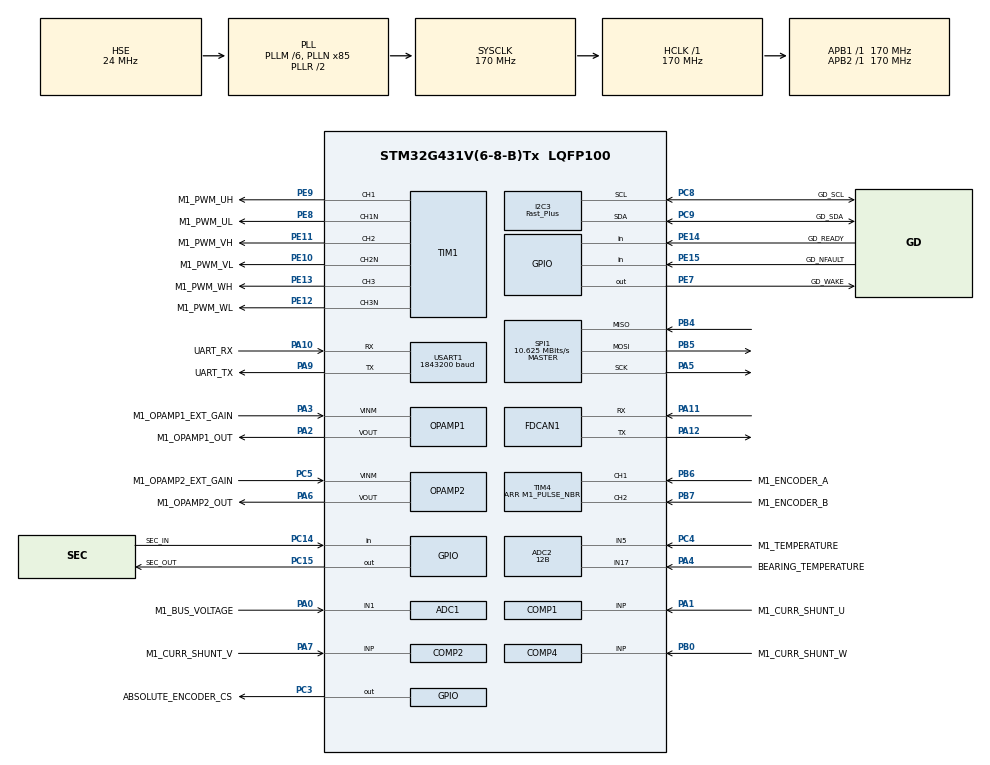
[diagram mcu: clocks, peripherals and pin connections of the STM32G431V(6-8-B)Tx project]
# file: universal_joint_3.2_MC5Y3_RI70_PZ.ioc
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ADC1.Channel-1\#ChannelRegularConversion=ADC_CHANNEL_1
ADC1.ClockPrescaler=ADC_CLOCK_ASYNC_DIV1
ADC1.ContinuousConvMode=DISABLE
ADC1.DMAContinuousRequests=DISABLE
ADC1.DataAlign=ADC_DATAALIGN_LEFT
ADC1.DiscontinuousConvMode=DISABLE
ADC1.EOCSelection=ADC_EOC_SINGLE_CONV
ADC1.EnableAnalogWatchDog1=false
ADC1.EnableAnalogWatchDog2=false
ADC1.EnableAnalogWatchDog3=false
ADC1.EnableInjectedConversion=ENABLE
ADC1.EnableRegularConversion=ENABLE
ADC1.ExternalTrigConv=ADC_SOFTWARE_START
ADC1.ExternalTrigConvEdge=ADC_EXTERNALTRIGCONVEDGE_NONE
ADC1.ExternalTrigInjecConv=ADC_EXTERNALTRIGINJEC_T1_TRGO
ADC1.ExternalTrigInjecConvEdge=ADC_EXTERNALTRIGINJECCONV_EDGE_RISING
ADC1.InjNumberOfConversion=1
ADC1.InjectedChannel-1\#ChannelInjectedConversion=ADC_CHANNEL_3
ADC1.InjectedConvMode=None
ADC1.InjectedOffset-1\#ChannelInjectedConversion=0
ADC1.InjectedOffsetNumber-1\#ChannelInjectedConversion=ADC_OFFSET_NONE
ADC1.InjectedRank-1\#ChannelInjectedConversion=1
ADC1.InjectedSamplingTime-1\#ChannelInjectedConversion=ADC_SAMPLETIME_6CYCLES_5
ADC1.LowPowerAutoWait=DISABLE
ADC1.NbrOfConversion=1
ADC1.NbrOfConversionFlag=1
ADC1.Offset-1\#ChannelRegularConversion=0
ADC1.OffsetNumber-1\#ChannelRegularConversion=ADC_OFFSET_NONE
ADC1.Overrun=ADC_OVR_DATA_PRESERVED
ADC1.Rank-1\#ChannelRegularConversion=1
ADC1.Resolution=ADC_RESOLUTION_12B
ADC1.SamplingTime-1\#ChannelRegularConversion=ADC_SAMPLETIME_47CYCLES_5
ADC1.ScanConvMode=ADC_SCAN_DISABLE
ADC1.master=1
ADC2.Channel-1\#ChannelRegularConversion=ADC_CHANNEL_5
ADC2.Channel-2\#ChannelRegularConversion=ADC_CHANNEL_17
ADC2.ClockPrescaler=ADC_CLOCK_ASYNC_DIV1
ADC2.ContinuousConvMode=DISABLE
ADC2.DMAContinuousRequests=DISABLE
ADC2.DataAlign=ADC_DATAALIGN_LEFT
ADC2.DiscontinuousConvMode=DISABLE
ADC2.EOCSelection=ADC_EOC_SINGLE_CONV
ADC2.EnableAnalogWatchDog1=false
ADC2.EnableAnalogWatchDog2=false
ADC2.EnableAnalogWatchDog3=false
ADC2.EnableInjectedConversion=ENABLE
ADC2.EnableRegularConversion=ENABLE
ADC2.ExternalTrigConv=ADC_SOFTWARE_START
ADC2.ExternalTrigConvEdge=ADC_EXTERNALTRIGCONVEDGE_NONE
ADC2.ExternalTrigInjecConv=ADC_EXTERNALTRIGINJEC_T1_TRGO
ADC2.ExternalTrigInjecConvEdge=ADC_EXTERNALTRIGINJECCONV_EDGE_RISING
ADC2.InjNumberOfConversion=1
ADC2.InjectedChannel-1\#ChannelInjectedConversion=ADC_CHANNEL_3
ADC2.InjectedConvMode=None
ADC2.InjectedOffset-1\#ChannelInjectedConversion=0
ADC2.InjectedOffsetNumber-1\#ChannelInjectedConversion=ADC_OFFSET_NONE
ADC2.InjectedRank-1\#ChannelInjectedConversion=1
ADC2.InjectedSamplingTime-1\#ChannelInjectedConversion=ADC_SAMPLETIME_6CYCLES_5
ADC2.LowPowerAutoWait=DISABLE
ADC2.NbrOfConversion=2
ADC2.NbrOfConversionFlag=1
ADC2.Offset-1\#ChannelRegularConversion=0
ADC2.OffsetNumber-1\#ChannelRegularConversion=ADC_OFFSET_NONE
ADC2.OffsetNumber-2\#ChannelRegularConversion=ADC_OFFSET_NONE
ADC2.Overrun=ADC_OVR_DATA_PRESERVED
ADC2.Rank-1\#ChannelRegularConversion=1
ADC2.Rank-2\#ChannelRegularConversion=2
ADC2.Resolution=ADC_RESOLUTION_12B
ADC2.SamplingTime-1\#ChannelRegularConversion=ADC_SAMPLETIME_47CYCLES_5
ADC2.SamplingTime-2\#ChannelRegularConversion=ADC_SAMPLETIME_47CYCLES_5
ADC2.ScanConvMode=ADC_SCAN_ENABLE
COMP1.Output=COMP_OUTPUT_TIM1BKIN2
COMP2.Output=COMP_OUTPUT_TIM1BKIN2
COMP4.Output=COMP_OUTPUT_TIM1BKIN2
Dma.Request0=USART1_RX
Dma.Request1=USART1_TX
Dma.Request2=SPI1_RX
Dma.Request3=SPI1_TX
Dma.SPI1_RX.2.Direction=DMA_PERIPH_TO_MEMORY
Dma.SPI1_RX.2.EventEnable=DISABLE
Dma.SPI1_RX.2.Instance=DMA1_Channel1
Dma.SPI1_RX.2.MemDataAlignment=DMA_MDATAALIGN_BYTE
Dma.SPI1_RX.2.MemInc=DMA_MINC_ENABLE
Dma.SPI1_RX.2.Mode=DMA_NORMAL
Dma.SPI1_RX.2.PeriphDataAlignment=DMA_PDATAALIGN_BYTE
Dma.SPI1_RX.2.PeriphInc=DMA_PINC_DISABLE
Dma.SPI1_RX.2.Polarity=HAL_DMAMUX_REQ_GEN_RISING
Dma.SPI1_RX.2.Priority=DMA_PRIORITY_LOW
Dma.SPI1_RX.2.RequestNumber=1
Dma.SPI1_RX.2.SignalID=NONE
Dma.SPI1_RX.2.SyncEnable=DISABLE
Dma.SPI1_RX.2.SyncPolarity=HAL_DMAMUX_SYNC_NO_EVENT
Dma.SPI1_RX.2.SyncRequestNumber=1
Dma.SPI1_RX.2.SyncSignalID=NONE
Dma.SPI1_TX.3.Direction=DMA_MEMORY_TO_PERIPH
Dma.SPI1_TX.3.EventEnable=DISABLE
Dma.SPI1_TX.3.Instance=DMA1_Channel4
Dma.SPI1_TX.3.MemDataAlignment=DMA_MDATAALIGN_BYTE
Dma.SPI1_TX.3.MemInc=DMA_MINC_ENABLE
Dma.SPI1_TX.3.Mode=DMA_NORMAL
Dma.SPI1_TX.3.PeriphDataAlignment=DMA_PDATAALIGN_BYTE
Dma.SPI1_TX.3.PeriphInc=DMA_PINC_DISABLE
Dma.SPI1_TX.3.Polarity=HAL_DMAMUX_REQ_GEN_RISING
Dma.SPI1_TX.3.Priority=DMA_PRIORITY_LOW
Dma.SPI1_TX.3.RequestNumber=1
Dma.SPI1_TX.3.SignalID=NONE
Dma.SPI1_TX.3.SyncEnable=DISABLE
Dma.SPI1_TX.3.SyncPolarity=HAL_DMAMUX_SYNC_NO_EVENT
Dma.SPI1_TX.3.SyncRequestNumber=1
Dma.SPI1_TX.3.SyncSignalID=NONE
Dma.USART1_RX.0.Direction=DMA_PERIPH_TO_MEMORY
Dma.USART1_RX.0.EventEnable=DISABLE
Dma.USART1_RX.0.Instance=DMA1_Channel2
Dma.USART1_RX.0.MemDataAlignment=DMA_MDATAALIGN_BYTE
Dma.USART1_RX.0.MemInc=DMA_MINC_ENABLE
Dma.USART1_RX.0.Mode=DMA_NORMAL
Dma.USART1_RX.0.PeriphDataAlignment=DMA_PDATAALIGN_BYTE
Dma.USART1_RX.0.PeriphInc=DMA_PINC_DISABLE
Dma.USART1_RX.0.Polarity=HAL_DMAMUX_REQ_GEN_RISING
Dma.USART1_RX.0.Priority=DMA_PRIORITY_LOW
Dma.USART1_RX.0.RequestNumber=1
Dma.USART1_RX.0.SignalID=NONE
Dma.USART1_RX.0.SyncEnable=DISABLE
Dma.USART1_RX.0.SyncPolarity=HAL_DMAMUX_SYNC_NO_EVENT
Dma.USART1_RX.0.SyncRequestNumber=1
Dma.USART1_RX.0.SyncSignalID=NONE
Dma.USART1_TX.1.Direction=DMA_MEMORY_TO_PERIPH
Dma.USART1_TX.1.EventEnable=DISABLE
Dma.USART1_TX.1.Instance=DMA1_Channel3
Dma.USART1_TX.1.MemDataAlignment=DMA_MDATAALIGN_BYTE
Dma.USART1_TX.1.MemInc=DMA_MINC_ENABLE
Dma.USART1_TX.1.Mode=DMA_NORMAL
Dma.USART1_TX.1.PeriphDataAlignment=DMA_PDATAALIGN_BYTE
Dma.USART1_TX.1.PeriphInc=DMA_PINC_DISABLE
Dma.USART1_TX.1.Polarity=HAL_DMAMUX_REQ_GEN_RISING
Dma.USART1_TX.1.Priority=DMA_PRIORITY_LOW
Dma.USART1_TX.1.RequestNumber=1
Dma.USART1_TX.1.SignalID=NONE
Dma.USART1_TX.1.SyncEnable=DISABLE
Dma.USART1_TX.1.SyncPolarity=HAL_DMAMUX_SYNC_NO_EVENT
Dma.USART1_TX.1.SyncRequestNumber=1
Dma.USART1_TX.1.SyncSignalID=NONE
ExtraMW=MotorControl
ExtraMW.MotorControl.Config=MotorControl
ExtraMW.MotorControl.Mode=MotorControl
ExtraMW.MotorControl.Root=MCSDK_v5.Y.3/MotorControl
ExtraMW.MotorControl.Template=templates
FDCAN1.AutoRetransmission=ENABLE
FDCAN1.ClockDivider=FDCAN_CLOCK_DIV2
FDCAN1.DataSyncJumpWidth=2
FDCAN1.DataTimeSeg1=12
FDCAN1.DataTimeSeg2=4
FDCAN1.FrameFormat=FDCAN_FRAME_FD_BRS
FDCAN1.NominalPrescaler=5
FDCAN1.NominalSyncJumpWidth=2
FDCAN1.NominalTimeSeg1=12
FDCAN1.NominalTimeSeg2=4
FDCAN1.StdFiltersNbr=2
FDCAN1.TransmitPause=ENABLE
I2C3.I2C_Speed_Mode=I2C_Fast_Plus
I2C3.Timing=0x00802172
Mcu.Family=STM32G4
Mcu.Name=STM32G431V(6-8-B)Tx
Mcu.Package=LQFP100
MotorControl.ADC_1_PERIPH=ADC1
MotorControl.ADC_2_PERIPH=ADC2
MotorControl.ADC_AHBPERIPH=RCC_AHBPeriph_ADC12
MotorControl.ADC_CLOCK_WB_DIV=1
MotorControl.ADC_CLOCK_WB_FREQ=42.5
MotorControl.ADC_PERIPH=ADC1
MotorControl.ADC_REFERENCE_VOLTAGE=3.30
MotorControl.ALIGNMENT_ANGLE_DEG=90
MotorControl.ALIGNMENT_DURATION=4000
MotorControl.AMPLIFICATION_GAIN=7.33
MotorControl.ANGC={0,0,0,0,0,0,0,0}
MotorControl.BEMF_CONSISTENCY_GAIN=64
MotorControl.BEMF_CONSISTENCY_TOL=64
MotorControl.BKIN1_FILTER=0
MotorControl.BKIN2_FILTER=5
MotorControl.BKIN2_MODE=NONE
MotorControl.BKIN_MODE=NONE
MotorControl.BOARD=EVSPIN32G4
MotorControl.BRKIN2_GPIO_AF=GPIO_AF_12
MotorControl.BRKIN_GPIO_AF=GPIO_AF_2
MotorControl.BUS_VOLTAGE_READING=true
MotorControl.CCMRAM_ENABLED=false
MotorControl.CLOCK_FREQUENCY=CPU_CLK_170_MHZ
MotorControl.CLOCK_SOURCE=EXTERNAL
MotorControl.CONSTANT1_D=147155
MotorControl.CONSTANT1_Q=147155
MotorControl.CONSTANT2_QD=10122
MotorControl.CORD_BEMF_CONSISTENCY_GAIN=64
MotorControl.CORD_BEMF_CONSISTENCY_TOL=64
MotorControl.CORD_F1=16384
MotorControl.CORD_F2=8192
MotorControl.CORD_FIFO_DEPTH_01HZ=64
MotorControl.CORD_FIFO_DEPTH_DPP=64
MotorControl.CORD_GAIN1=-23688
MotorControl.CORD_GAIN2=17461
MotorControl.CORD_MAX_ACCEL_DPPP=540
MotorControl.CORD_MEAS_ERRORS_BEFORE_FAULTS=3
MotorControl.CORD_VARIANCE_THRESHOLD=4
MotorControl.CPU_CLK_170_MHZ=true
MotorControl.CTRBDID=10021
MotorControl.CUBE_MX_VER=6.3.0
MotorControl.CURRENT_READING_TOPOLOGY=THREE_SHUNT_INDEPENDENT_RESOURCES
MotorControl.CURR_SAMPLING_TIME=6
MotorControl.DAC_EMULATED=false
MotorControl.DAC_FUNCTIONALITY=false
MotorControl.DAC_TIMER_CH1_GPIO_PIN=LL_GPIO_PIN_0
MotorControl.DAC_TIMER_CH1_GPIO_PORT=GPIOA
MotorControl.DAC_TIMER_CH2_GPIO_PIN=LL_GPIO_PIN_0
MotorControl.DAC_TIMER_CH2_GPIO_PORT=GPIOA
MotorControl.DAC_TIMER_SELECTION=TIM3
MotorControl.DC_CURRENT_RS_MEAS=8.00
MotorControl.DEBUG_DAC_CH1=false
MotorControl.DEBUG_DAC_CH2=false
MotorControl.DEFAULT_CONTROL_MODE=STC_TORQUE_MODE
MotorControl.DEFAULT_DAC_CHANNEL_1=MC_PROTOCOL_REG_I_A
MotorControl.DEFAULT_DAC_CHANNEL_2=MC_PROTOCOL_REG_I_B
MotorControl.DEFAULT_DAC_MOTOR=0
MotorControl.DEFAULT_FLUX_COMPONENT=0
MotorControl.DEFAULT_TARGET_SPEED_RPM=734
MotorControl.DEFAULT_TORQUE_COMPONENT=0
MotorControl.DISCONTINUOUS_PWM=false
MotorControl.DISSIPATIVE_BRAKE_POLARITY=DOUT_ACTIVE_HIGH
MotorControl.DRIVES_NUMBER_SELECTION=SINGLEDRIVE
MotorControl.EMERGENCY2_STOP_GPIO_PIN=LL_GPIO_PIN_11
MotorControl.EMERGENCY2_STOP_GPIO_PORT=GPIOA
MotorControl.EMERGENCY_STOP_GPIO_PIN=LL_GPIO_PIN_11
MotorControl.EMERGENCY_STOP_GPIO_PORT=GPIOA
MotorControl.ENABLE_SL_ALGO_FROM_PHASE=2
MotorControl.ENCODER=true
MotorControl.ENCODER_AVAILABLE=true
MotorControl.ENCODER_PPR=2500
MotorControl.ENC_AVERAGING_FIFO_DEPTH=16
MotorControl.ENC_A_GPIO_PIN=LL_GPIO_PIN_6
MotorControl.ENC_A_GPIO_PORT=GPIOB
MotorControl.ENC_B_GPIO_PIN=LL_GPIO_PIN_7
MotorControl.ENC_B_GPIO_PORT=GPIOB
MotorControl.ENC_ICx_FILTER=128
MotorControl.ENC_INVERT_SPEED=false
MotorControl.ENC_MEAS_ERRORS_BEFORE_FAULTS=3
MotorControl.ENC_TIMER_REMAPPING=NO_REMAP_TIM4
MotorControl.ENC_TIMER_SELECTION=ENC_TIM4
MotorControl.ENC_USE_CH3=false
MotorControl.EXT_CLK_24_MHZ=true
MotorControl.EXT_CLOCK_FREQUENCY=EXT_CLK_24_MHZ
MotorControl.F1=16384
MotorControl.F2=8192
MotorControl.FEEDBACK_NET_FILTERING=false
MotorControl.FEED_FORWARD_CURRENT_REG_ENABLING=false
MotorControl.FINAL_I_ALIGNMENT=5822
MotorControl.FLUX_WEAKENING_ENABLING=false
MotorControl.FW_KIDIV=32768
MotorControl.FW_KI_GAIN=5000
MotorControl.FW_KPDIV=32768
MotorControl.FW_KP_GAIN=3000
MotorControl.FW_VOLTAGE_REF=985
MotorControl.GAIN1=-23688
MotorControl.GAIN2=17461
MotorControl.H1_GPIO_PIN=LL_GPIO_PIN_6
MotorControl.H1_GPIO_PORT=GPIOB
MotorControl.H2_GPIO_PIN=LL_GPIO_PIN_7
MotorControl.H2_GPIO_PORT=GPIOB
MotorControl.H3_GPIO_PIN=LL_GPIO_PIN_8
MotorControl.H3_GPIO_PORT=GPIOB
MotorControl.HALL_AVERAGING_FIFO_DEPTH=6
MotorControl.HALL_ICx_FILTER=221
MotorControl.HALL_MEAS_ERRORS_BEFORE_FAULTS=3
MotorControl.HALL_MTPA=false
MotorControl.HALL_PHASE_SHIFT=300
MotorControl.HALL_SENSORS_AVAILABLE=false
MotorControl.HALL_SENSORS_PLACEMENT=DEGREES_120
MotorControl.HALL_TIMER_REMAPPING=NO_REMAP_TIM4
MotorControl.HALL_TIMER_SELECTION=HALL_TIM4
MotorControl.HFI_AMPLITUDE=25
MotorControl.HFI_DC_0_COEFF=0.00146
MotorControl.HFI_DC_1_COEFF=0.002921
MotorControl.HFI_DC_2_COEFF=0.00146
MotorControl.HFI_DC_3_COEFF=1.889033
MotorControl.HFI_DC_4_COEFF=-0.894874
MotorControl.HFI_DEBUG_MODE=false
MotorControl.HFI_FREQUENCY=400
MotorControl.HFI_HIFRAMPLSCAN=25
MotorControl.HFI_HP_ID_0_COEFF=0.883002
MotorControl.HFI_HP_ID_1_COEFF=-1.766004
MotorControl.HFI_HP_ID_2_COEFF=0.883002
MotorControl.HFI_HP_ID_3_COEFF=1.752268
MotorControl.HFI_HP_ID_4_COEFF=-0.779739
MotorControl.HFI_IDH_DELAY=32400
MotorControl.HFI_LOCKFREQ=66
MotorControl.HFI_LP_ID_0_COEFF=0.021558
MotorControl.HFI_LP_ID_1_COEFF=0.043117
MotorControl.HFI_LP_ID_2_COEFF=0.021558
MotorControl.HFI_LP_ID_3_COEFF=1.543836
MotorControl.HFI_LP_ID_4_COEFF=-0.63007
MotorControl.HFI_MAXANGLEDIFF=3640
MotorControl.HFI_MINIMUM_SPEED_RPM=402
MotorControl.HFI_NOTCH_IQD_0_COEFF=0.941467
MotorControl.HFI_NOTCH_IQD_1_COEFF=-1.823778
MotorControl.HFI_NOTCH_IQD_2_COEFF=0.941467
MotorControl.HFI_NOTCH_IQD_3_COEFF=1.823778
MotorControl.HFI_NOTCH_IQD_4_COEFF=-0.882933
MotorControl.HFI_NSDETPOINTSSKIP=10
MotorControl.HFI_NSMAXDETPOINTS=20
MotorControl.HFI_NS_MIN_SAT_DIFF=0
MotorControl.HFI_PID_KIDIV=32768
MotorControl.HFI_PID_KI_DEFAULT=400
MotorControl.HFI_PID_KPDIV=16384
MotorControl.HFI_PID_KP_DEFAULT=800
MotorControl.HFI_PLL_KI_DEFAULT=0.00400
MotorControl.HFI_PLL_KP_DEFAULT=0.00060
MotorControl.HFI_RESTARTTIMESEC=0.1
MotorControl.HFI_RESTART_RPM_TH=(((HFI_STO_RPM_TH)+(STO_HFI_RPM_TH))/2)
MotorControl.HFI_REVERT_DIRECTION=true
MotorControl.HFI_SCANROTATIONSNO=3
MotorControl.HFI_SPD_BUFFER_DEPTH_01HZ=64
MotorControl.HFI_STEPANGLE=3640
MotorControl.HFI_STO_RPM_TH=OBS_MINIMUM_SPEED_RPM
MotorControl.HFI_WAITAFTERNS2=4
MotorControl.HFI_WAITBEFORESN=6
MotorControl.HFI_WAITSYNCH=20
MotorControl.HFI_WAITTRACK=20
MotorControl.HIGH_SIDE_BRAKE_STATE=false
MotorControl.HIGH_SIDE_IDLE_STATE=false
MotorControl.HW_COMPLEMENTED_LOW_SIDE=false
MotorControl.HW_DEAD_TIME_NS=100
MotorControl.HW_OV_CURRENT_PROT_BYPASS=false
MotorControl.ID_DEMAG=-5822
MotorControl.INRUSH_CURRLIMIT_AT_POWER_ON=true
MotorControl.INRUSH_CURRLIMIT_CHANGE_AFTER_MS=1000
MotorControl.INRUSH_CURRLIMIT_ENABLING=false
MotorControl.INRUSH_CURRLIMIT_GPIO_PIN=LL_GPIO_PIN_10
MotorControl.INRUSH_CURRLIMIT_GPIO_PORT=GPIOC
MotorControl.INRUSH_CURR_LIMITER_POLARITY=DOUT_ACTIVE_HIGH
MotorControl.INTERNAL_OVERCURRENTPROTECTION=false
MotorControl.INTERNAL_OVERVOLTAGEPROTECTION=false
MotorControl.IPs=NVIC,RCC,SYS,I2C3,CORDIC,MotorControl,TIM1,COMP1,COMP2,COMP4,OPAMP1,OPAMP2,ADC1,ADC2,TIM4,USART1,DMA
MotorControl.IQMAX=5822
MotorControl.LCD_JOYSTICK_FUNCTIONALITY=false
MotorControl.LCD_MODE=LCD_FULL
MotorControl.LDLQ_RATIO=1.000
MotorControl.LOW_SIDE_BRAKE_STATE=false
MotorControl.LOW_SIDE_IDLE_STATE=true
MotorControl.LOW_SIDE_SIGNALS_ENABLING=LS_PWM_TIMER
MotorControl.LS=0.000263
MotorControl.MAX_APPLICATION_SPEED=2826
MotorControl.MAX_MODULATION_81_PER_CENT=true
MotorControl.MAX_MODULATION_INDEX=MAX_MODULATION_81_PER_CENT
MotorControl.MCU=STSPIN32G4
MotorControl.MCU_TYPE=STSPIN32G4
MotorControl.MC_WORKBENCH_VERSION=5.Y.2.21279
MotorControl.MEAS_ERRORS_BEFORE_FAULTS=3
MotorControl.MIN_APPLICATION_SPEED=0
MotorControl.MOTOR_MAX_SPEED_RPM=2826
MotorControl.MOTOR_TYPE=PMSM
MotorControl.MOTOR_VOLTAGE_CONSTANT=11.7
MotorControl.MTPA_ENABLING=false
MotorControl.NB_CONSECUTIVE_TESTS=2
MotorControl.NOMINAL_BUS_VOLTAGE_V=48
MotorControl.NOMINAL_CURRENT=5822
MotorControl.OBS_MEAS_ERRORS_BEFORE_FAULTS=3
MotorControl.OBS_MINIMUM_SPEED_RPM=734
MotorControl.OCPA_INVERTINGINPUT=COMPX_InvertingInput_VREF_1_4
MotorControl.OCPA_INVERTINGINPUT_GPIO_PIN=LL_GPIO_PIN_4
MotorControl.OCPA_INVERTINGINPUT_GPIO_PORT=GPIOA
MotorControl.OCPA_INVERTINGINPUT_MODE=INT_MODE
MotorControl.OCPA_NONINVERTINGINPUT=COMP1_NonInvertingInput_PA1
MotorControl.OCPA_NONINVERTINGINPUT_GPIO_PIN=LL_GPIO_PIN_1
MotorControl.OCPA_NONINVERTINGINPUT_GPIO_PORT=GPIOA
MotorControl.OCPA_OUTPUT=COMP_Output_TIM1BKIN2
MotorControl.OCPA_OUTPUTPOL=COMP_OutputPol_NonInverted
MotorControl.OCPA_OUTPUT_GPIO_AF=GPIO_AF_2
MotorControl.OCPA_OUTPUT_GPIO_PIN=LL_GPIO_PIN_0
MotorControl.OCPA_OUTPUT_GPIO_PORT=GPIOA
MotorControl.OCPA_OUTPUT_MODE=INT_MODE
MotorControl.OCPA_SELECTION=COMP1
MotorControl.OCPB_INVERTINGINPUT=COMPX_InvertingInput_VREF_1_4
MotorControl.OCPB_INVERTINGINPUT_GPIO_PIN=LL_GPIO_PIN_4
MotorControl.OCPB_INVERTINGINPUT_GPIO_PORT=GPIOA
MotorControl.OCPB_INVERTINGINPUT_MODE=INT_MODE
MotorControl.OCPB_NONINVERTINGINPUT=COMP2_NonInvertingInput_PA7
MotorControl.OCPB_NONINVERTINGINPUT_GPIO_PIN=LL_GPIO_PIN_7
MotorControl.OCPB_NONINVERTINGINPUT_GPIO_PORT=GPIOA
MotorControl.OCPB_OUTPUT=COMP_Output_TIM1BKIN2
MotorControl.OCPB_OUTPUTPOL=COMP_OutputPol_NonInverted
MotorControl.OCPB_OUTPUT_GPIO_AF=GPIO_AF_2
MotorControl.OCPB_OUTPUT_GPIO_PIN=LL_GPIO_PIN_2
MotorControl.OCPB_OUTPUT_GPIO_PORT=GPIOA
MotorControl.OCPB_OUTPUT_MODE=INT_MODE
MotorControl.OCPB_SELECTION=COMP2
MotorControl.OCPC_INVERTINGINPUT=COMPX_InvertingInput_VREF_1_4
MotorControl.OCPC_INVERTINGINPUT_GPIO_PIN=LL_GPIO_PIN_4
MotorControl.OCPC_INVERTINGINPUT_GPIO_PORT=GPIOA
MotorControl.OCPC_INVERTINGINPUT_MODE=INT_MODE
MotorControl.OCPC_NONINVERTINGINPUT=COMP4_NonInvertingInput_PB0
MotorControl.OCPC_NONINVERTINGINPUT_GPIO_PIN=LL_GPIO_PIN_0
MotorControl.OCPC_NONINVERTINGINPUT_GPIO_PORT=GPIOB
MotorControl.OCPC_OUTPUT=COMP_Output_TIM1BKIN2
MotorControl.OCPC_OUTPUTPOL=COMP_OutputPol_NonInverted
MotorControl.OCPC_OUTPUT_GPIO_AF=GPIO_AF_2
MotorControl.OCPC_OUTPUT_GPIO_PIN=LL_GPIO_PIN_1
MotorControl.OCPC_OUTPUT_GPIO_PORT=GPIOB
MotorControl.OCPC_OUTPUT_MODE=INT_MODE
MotorControl.OCPC_SELECTION=COMP4
MotorControl.OCPREF=5957
MotorControl.OCP_COMP_THRESHOLD=0.30
MotorControl.OCP_FILTER=COMP_Mode_HighSpeed
MotorControl.OCP_INVERTINGINPUT=COMPX_InvertingInput_VREF_1_4
MotorControl.OCP_INVERTINGINPUT_GPIO_PIN=LL_GPIO_PIN_4
MotorControl.OCP_INVERTINGINPUT_GPIO_PORT=GPIOA
MotorControl.OCP_INVERTINGINPUT_MODE=INT_MODE
MotorControl.OCP_NONINVERTINGINPUT=COMP2_NonInvertingInput_PA7
MotorControl.OCP_NONINVERTINGINPUT_GPIO_PIN=LL_GPIO_PIN_7
MotorControl.OCP_NONINVERTINGINPUT_GPIO_PORT=GPIOA
MotorControl.OCP_OUTPUT=COMP_Output_TIM1BKIN2
MotorControl.OCP_OUTPUTPOL=COMP_OutputPol_NonInverted
MotorControl.OCP_OUTPUT_GPIO_AF=GPIO_AF_2
MotorControl.OCP_OUTPUT_GPIO_PIN=LL_GPIO_PIN_2
MotorControl.OCP_OUTPUT_GPIO_PORT=GPIOA
MotorControl.OCP_OUTPUT_MODE=INT_MODE
MotorControl.OCP_SELECTION=COMP2
MotorControl.OFST={0,0,0,0,0,0,0,0}
MotorControl.ON_OVER_VOLTAGE=TURN_ON_LOW_SIDES
MotorControl.OPAMP1_INVERTINGINPUT=OPAMP1_InvertingInput_PA3
MotorControl.OPAMP1_INVERTINGINPUT_GPIO_PIN=LL_GPIO_PIN_3
MotorControl.OPAMP1_INVERTINGINPUT_GPIO_PORT=GPIOA
MotorControl.OPAMP1_INVERTINGINPUT_MODE=EXT_MODE
MotorControl.OPAMP1_NONINVERTINGINPUT_PHA=OPAMP1_NonInvertingInput_PA1
MotorControl.OPAMP1_NONINVERTINGINPUT_PHA_GPIO_PIN=LL_GPIO_PIN_1
MotorControl.OPAMP1_NONINVERTINGINPUT_PHA_GPIO_PORT=GPIOA
MotorControl.OPAMP1_NONINVERTINGINPUT_PHB=OPAMP1_NonInvertingInput_PA7
MotorControl.OPAMP1_NONINVERTINGINPUT_PHB_GPIO_PIN=LL_GPIO_PIN_7
MotorControl.OPAMP1_NONINVERTINGINPUT_PHB_GPIO_PORT=GPIOA
MotorControl.OPAMP1_OUT_GPIO_PIN=LL_GPIO_PIN_2
MotorControl.OPAMP1_OUT_GPIO_PORT=GPIOA
MotorControl.OPAMP1_SELECTION=OPAMP1
MotorControl.OPAMP2_INVERTINGINPUT=OPAMP2_InvertingInput_PC5
MotorControl.OPAMP2_INVERTINGINPUT_GPIO_PIN=LL_GPIO_PIN_5
MotorControl.OPAMP2_INVERTINGINPUT_GPIO_PORT=GPIOC
MotorControl.OPAMP2_INVERTINGINPUT_MODE=EXT_MODE
MotorControl.OPAMP2_NONINVERTINGINPUT_PHA=OPAMP2_NonInvertingInput_PB0
MotorControl.OPAMP2_NONINVERTINGINPUT_PHA_GPIO_PIN=LL_GPIO_PIN_0
MotorControl.OPAMP2_NONINVERTINGINPUT_PHA_GPIO_PORT=GPIOB
MotorControl.OPAMP2_NONINVERTINGINPUT_PHB=OPAMP2_NonInvertingInput_PA7
MotorControl.OPAMP2_NONINVERTINGINPUT_PHB_GPIO_PIN=LL_GPIO_PIN_7
MotorControl.OPAMP2_NONINVERTINGINPUT_PHB_GPIO_PORT=GPIOA
MotorControl.OPAMP2_NONINVERTINGINPUT_PHC=OPAMP2_NonInvertingInput_PB0
MotorControl.OPAMP2_NONINVERTINGINPUT_PHC_GPIO_PIN=LL_GPIO_PIN_0
MotorControl.OPAMP2_NONINVERTINGINPUT_PHC_GPIO_PORT=GPIOB
MotorControl.OPAMP2_OUT_GPIO_PIN=LL_GPIO_PIN_6
MotorControl.OPAMP2_OUT_GPIO_PORT=GPIOA
MotorControl.OPAMP2_SELECTION=OPAMP2
MotorControl.OPAMP3_INVERTINGINPUT=OPAMP1_InvertingInput_PA0
MotorControl.OPAMP3_INVERTINGINPUT_GPIO_PIN=LL_GPIO_PIN_0
MotorControl.OPAMP3_INVERTINGINPUT_GPIO_PORT=GPIOA
MotorControl.OPAMP3_INVERTINGINPUT_MODE=EXT_MODE
MotorControl.OPAMP3_SELECTION=OPAMP1
MotorControl.OPAMP_INVERTINGINPUT=OPAMP1_InvertingInput_PA3
MotorControl.OPAMP_INVERTINGINPUT_GPIO_PIN=LL_GPIO_PIN_3
MotorControl.OPAMP_INVERTINGINPUT_GPIO_PORT=GPIOA
MotorControl.OPAMP_INVERTINGINPUT_MODE=EXT_MODE
MotorControl.OPAMP_NONINVERTINGINPUT=OPAMP1_NonInvertingInput_PA7
MotorControl.OPAMP_NONINVERTINGINPUT_GPIO_PIN=LL_GPIO_PIN_7
MotorControl.OPAMP_NONINVERTINGINPUT_GPIO_PORT=GPIOA
MotorControl.OPAMP_OUT_GPIO_PIN=LL_GPIO_PIN_2
MotorControl.OPAMP_OUT_GPIO_PORT=GPIOA
MotorControl.OPAMP_PGACONNECT=OPAMP1_PGAConnect_PA3
MotorControl.OPAMP_PGAGAIN=OPAMP_OPAMP_PGAGain_8
MotorControl.OPAMP_SELECTION=OPAMP1
MotorControl.OPAMP_TYPE_GAIN=EXTERNAL
MotorControl.OPEN_LOOP_FOC=false
MotorControl.OPEN_LOOP_K=44
MotorControl.OPEN_LOOP_OFF=4400
MotorControl.OPEN_LOOP_SPEED_RAMP_DURATION_MS=1000
MotorControl.OPEN_LOOP_SPEED_RPM=100
MotorControl.OPEN_LOOP_VF=false
MotorControl.OPEN_LOOP_VOLTAGE_d=6000
MotorControl.OVERCURR_FEEDBACK_POLARITY=EMSTOP_ACTIVE_LOW
MotorControl.OVERCURR_PROTECTION_HW_DISABLING=DOUT_ACTIVE_HIGH
MotorControl.OVERMODULATION=false
MotorControl.OVPREF=23830
MotorControl.OVP_FILTER=COMP_Mode_HighSpeed
MotorControl.OVP_INVERTINGINPUT=COMPX_InvertingInput_VREF
MotorControl.OVP_INVERTINGINPUT_GPIO_PIN=LL_GPIO_PIN_4
MotorControl.OVP_INVERTINGINPUT_GPIO_PORT=GPIOA
MotorControl.OVP_INVERTINGINPUT_MODE=INT_MODE
MotorControl.OVP_NONINVERTINGINPUT=COMP2_NonInvertingInput_PA7
MotorControl.OVP_NONINVERTINGINPUT_GPIO_PIN=LL_GPIO_PIN_7
MotorControl.OVP_NONINVERTINGINPUT_GPIO_PORT=GPIOA
MotorControl.OVP_OUTPUT=COMP_Output_TIM1BKIN
MotorControl.OVP_OUTPUTPOL=COMP_OutputPol_NonInverted
MotorControl.OVP_OUTPUT_GPIO_AF=GPIO_AF_2
MotorControl.OVP_OUTPUT_GPIO_PIN=LL_GPIO_PIN_2
MotorControl.OVP_OUTPUT_GPIO_PORT=GPIOA
MotorControl.OVP_OUTPUT_MODE=INT_MODE
MotorControl.OVP_SELECTION=COMP2
MotorControl.OV_CURR_BYPASS_GPIO_PIN=LL_GPIO_PIN_11
MotorControl.OV_CURR_BYPASS_GPIO_PORT=GPIOC
MotorControl.OV_TEMPERATURE_HYSTERESIS_C=10
MotorControl.OV_TEMPERATURE_PROT_ENABLING=true
MotorControl.OV_TEMPERATURE_THRESHOLD_C=90
MotorControl.OV_VOLTAGE_PROT_ENABLING=true
MotorControl.OV_VOLTAGE_THRESHOLD_V=75
MotorControl.PHASE1_DURATION=1000
MotorControl.PHASE1_FINAL_CURRENT=5822
MotorControl.PHASE1_FINAL_SPEED_RPM=0
MotorControl.PHASE2_DURATION=1632
MotorControl.PHASE2_FINAL_CURRENT=5822
MotorControl.PHASE2_FINAL_SPEED_RPM=816
MotorControl.PHASE3_DURATION=0
MotorControl.PHASE3_FINAL_CURRENT=5822
MotorControl.PHASE3_FINAL_SPEED_RPM=816
MotorControl.PHASE4_DURATION=0
MotorControl.PHASE4_FINAL_CURRENT=5822
MotorControl.PHASE4_FINAL_SPEED_RPM=816
MotorControl.PHASE5_DURATION=0
MotorControl.PHASE5_FINAL_CURRENT=5822
MotorControl.PHASE5_FINAL_SPEED_RPM=816
MotorControl.PHASE_CURRENTS_ADC=ADC1_2
MotorControl.PHASE_CURRENTS_CHANNEL=ADC_CHANNEL_7
MotorControl.PHASE_CURRENTS_GPIO_PIN=LL_GPIO_PIN_1
MotorControl.PHASE_CURRENTS_GPIO_PORT=GPIOC
MotorControl.PHASE_UH_GPIO_AF=GPIO_AF_2
MotorControl.PHASE_UH_GPIO_PIN=LL_GPIO_PIN_9
MotorControl.PHASE_UH_GPIO_PORT=GPIOE
MotorControl.PHASE_UH_POLARITY=H_ACTIVE_HIGH
MotorControl.PHASE_UL_GPIO_AF=GPIO_AF_2
MotorControl.PHASE_UL_GPIO_PIN=LL_GPIO_PIN_8
MotorControl.PHASE_UL_GPIO_PORT=GPIOE
MotorControl.PHASE_UL_POLARITY=L_ACTIVE_HIGH
MotorControl.PHASE_U_CURR_ADC=ADC1
MotorControl.PHASE_U_CURR_CHANNEL=ADC_CHANNEL_3
MotorControl.PHASE_U_GPIO_PIN=LL_GPIO_PIN_2
MotorControl.PHASE_U_GPIO_PORT=GPIOA
MotorControl.PHASE_VH_GPIO_AF=GPIO_AF_2
MotorControl.PHASE_VH_GPIO_PIN=LL_GPIO_PIN_11
MotorControl.PHASE_VH_GPIO_PORT=GPIOE
MotorControl.PHASE_VH_POLARITY=H_ACTIVE_HIGH
MotorControl.PHASE_VL_GPIO_AF=GPIO_AF_2
MotorControl.PHASE_VL_GPIO_PIN=LL_GPIO_PIN_10
MotorControl.PHASE_VL_GPIO_PORT=GPIOE
MotorControl.PHASE_VL_POLARITY=L_ACTIVE_HIGH
MotorControl.PHASE_V_CURR_ADC=ADC2
MotorControl.PHASE_V_CURR_CHANNEL=ADC_CHANNEL_3
MotorControl.PHASE_V_GPIO_PIN=LL_GPIO_PIN_6
MotorControl.PHASE_V_GPIO_PORT=GPIOA
MotorControl.PHASE_WH_GPIO_AF=GPIO_AF_2
MotorControl.PHASE_WH_GPIO_PIN=LL_GPIO_PIN_13
MotorControl.PHASE_WH_GPIO_PORT=GPIOE
MotorControl.PHASE_WH_POLARITY=H_ACTIVE_HIGH
MotorControl.PHASE_WL_GPIO_AF=GPIO_AF_2
MotorControl.PHASE_WL_GPIO_PIN=LL_GPIO_PIN_12
MotorControl.PHASE_WL_GPIO_PORT=GPIOE
MotorControl.PHASE_WL_POLARITY=L_ACTIVE_HIGH
MotorControl.PHASE_W_CURR_ADC=ADC1_2
MotorControl.PHASE_W_CURR_CHANNEL=ADC_CHANNEL_6
MotorControl.PHASE_W_GPIO_PIN=LL_GPIO_PIN_0
MotorControl.PHASE_W_GPIO_PORT=GPIOC
MotorControl.PID_FLUX_KD_DEFAULT=100
MotorControl.PID_FLUX_KI_DEFAULT=350
MotorControl.PID_FLUX_KP_DEFAULT=2425
MotorControl.PID_SPEED_KD_DEFAULT=0
MotorControl.PID_SPEED_KI_DEFAULT=1110
MotorControl.PID_SPEED_KP_DEFAULT=2342
MotorControl.PID_TORQUE_KD_DEFAULT=100
MotorControl.PID_TORQUE_KI_DEFAULT=4000
MotorControl.PID_TORQUE_KP_DEFAULT=2425
MotorControl.PLL_KI_GAIN=149
MotorControl.PLL_KP_GAIN=2105
MotorControl.POLE_PAIR_NUM=14
MotorControl.POSITION_CTRL_ENABLING=false
MotorControl.PWBDID=10021
MotorControl.PWM_FREQUENCY=30000
MotorControl.PWM_TIMER_REMAPPING=PWM_PARTIAL_REMAP
MotorControl.PWM_TIMER_SELECTION=PWM_TIM1
MotorControl.REGCONVADC=ADC1
MotorControl.REGULATION_EXECUTION_RATE=3
MotorControl.RS=0.19
MotorControl.RSHUNT=0.00500
MotorControl.RTOS=NONE
MotorControl.R_BRAKE_GPIO_PIN=LL_GPIO_PIN_11
MotorControl.R_BRAKE_GPIO_PORT=GPIOC
MotorControl.R_BRAKE_SWITCH_OFF_THRES_V=60
MotorControl.SEGDIV=0
MotorControl.SERIAL_COMMUNICATION=true
MotorControl.SERIAL_COM_CHANNEL1=MC_PROTOCOL_REG_I_A
MotorControl.SERIAL_COM_CHANNEL2=MC_PROTOCOL_REG_I_A
MotorControl.SERIAL_COM_MODE=COM_BIDIRECTIONAL
MotorControl.SERIAL_COM_MOTOR=0
MotorControl.SHARED_SIGNAL_ENABLE=false
MotorControl.SINGLEDRIVE=true
MotorControl.SPD_DIFFERENTIAL_TERM_ENABLING=false
MotorControl.SPEED_BAND_LOWER_LIMIT=15
MotorControl.SPEED_BAND_UPPER_LIMIT=17
MotorControl.SPEED_LOOP_FREQUENCY_HZ=1000
MotorControl.SPEED_SENSOR_SELECTION=ENCODER
MotorControl.SP_KDDIV=16
MotorControl.SP_KIDIV=16384
MotorControl.SP_KPDIV=128
MotorControl.STARTING_ANGLE_DEG=0
MotorControl.START_STOP_BTN=false
MotorControl.START_STOP_GPIO_PIN=LL_GPIO_PIN_10
MotorControl.START_STOP_GPIO_PORT=GPIOB
MotorControl.START_STOP_POLARITY=DIN_ACTIVE_HIGH
MotorControl.START_STOP_POLARITY_EDGE=GPIO_NOPULL
MotorControl.STO_FIFO_DEPTH_01HZ=64
MotorControl.STO_FIFO_DEPTH_DPP=64
MotorControl.STO_HFI_RPM_TH=460
MotorControl.STSPIN32G4=true
MotorControl.SW_DEADTIME_NS=800
MotorControl.SW_OV_CURRENT_PROT_ENABLING=false
MotorControl.T0_C=23
MotorControl.TEMPERATURE_READING=true
MotorControl.TEMP_ADC_SAMPLING_TIME=47
MotorControl.TEMP_FDBK_ADC=ADC2
MotorControl.TEMP_FDBK_CHANNEL=ADC_CHANNEL_5
MotorControl.TEMP_FDBK_GPIO_PIN=LL_GPIO_PIN_4
MotorControl.TEMP_FDBK_GPIO_PORT=GPIOC
MotorControl.TFDIFFERENTIAL_TERM_ENABLING=false
MotorControl.TF_KDDIV=8192
MotorControl.TF_KIDIV=16384
MotorControl.TF_KPDIV=8192
MotorControl.THREE_SHUNT_INDEPENDENT_RESOURCES=true
MotorControl.TNOISE_NS=2550
MotorControl.TRANSITION_DURATION=25
MotorControl.TRISE_NS=500
MotorControl.T_MAX=90
MotorControl.UD_VOLTAGE_THRESHOLD_V=10
MotorControl.USART_REMAPPING=NO_REMAP_USART1
MotorControl.USART_RX_GPIO_PIN=LL_GPIO_PIN_10
MotorControl.USART_RX_GPIO_PORT=GPIOA
MotorControl.USART_SELECTION=USE_USART1
MotorControl.USART_SPEED=1843200
MotorControl.USART_TX_GPIO_PIN=LL_GPIO_PIN_9
MotorControl.USART_TX_GPIO_PORT=GPIOA
MotorControl.USE_3OPAMPS=false
MotorControl.USE_INTERNAL_OPAMP=true
MotorControl.UV_VOLTAGE_PROT_ENABLING=true
MotorControl.V0_V=1.000
MotorControl.VARIANCE_THRESHOLD=0.1
MotorControl.VBUS_ADC=ADC1
MotorControl.VBUS_ADC_SAMPLING_TIME=47
MotorControl.VBUS_CHANNEL=ADC_CHANNEL_1
MotorControl.VBUS_GPIO_PIN=LL_GPIO_PIN_0
MotorControl.VBUS_GPIO_PORT=GPIOA
MotorControl.VBUS_PARTITIONING_FACTOR=0.0398
MotorControl.WB_to_Mx_template_version=21-06-29
MotorControl.WB_to_Mx_version=1.5.0
MotorControl.dV_dT=0.025
NVIC.ADC1_2_IRQn=true\:2\:0\:true\:true\:false\:3\:true\:true
NVIC.DMA1_Channel1_IRQn=true\:7\:1\:true\:false\:true\:true\:true
NVIC.DMA1_Channel2_IRQn=true\:0\:0\:true\:true\:false\:6\:true\:true
NVIC.DMA1_Channel4_IRQn=true\:7\:1\:true\:false\:true\:true\:true
NVIC.FDCAN1_IT0_IRQn=true\:7\:0\:true\:false\:true\:true\:true
NVIC.PriorityGroup=NVIC_PRIORITYGROUP_3
NVIC.SPI1_IRQn=true\:7\:1\:true\:false\:true\:true\:true
NVIC.TIM1_BRK_TIM15_IRQn=true\:4\:1\:true\:true\:false\:1\:true\:true
NVIC.TIM1_UP_TIM16_IRQn=true\:0\:0\:false\:true\:false\:2\:true\:true
NVIC.TIM4_IRQn=true\:3\:0\:false\:true\:false\:4\:true\:true
NVIC.TIM6_DAC_IRQn=true\:6\:0\:true\:false\:true\:true\:true
NVIC.TIM7_IRQn=true\:6\:1\:true\:false\:true\:true\:true
NVIC.USART1_IRQn=true\:3\:1\:true\:true\:false\:5\:true\:true
OPAMP1.SelfCalibration=Disable
OPAMP2.SelfCalibration=Disable
PA0.GPIO_Label=M1_BUS_VOLTAGE
PA0.Mode=IN1-Single-Ended
PA0.Signal=ADC1_IN1
PA1.GPIO_Label=M1_CURR_SHUNT_U
PA1.Signal=SharedAnalog_PA1
PA10.GPIO_Label=UART_RX
PA10.GPIO_Mode=GPIO_MODE_AF_PP
PA10.GPIO_PuPd=GPIO_NOPULL
PA10.GPIO_Speed=GPIO_SPEED_FREQ_LOW
PA10.Mode=Asynchronous
PA10.Signal=USART1_RX
PA11.Mode=FDCAN_Activate
PA11.Signal=FDCAN1_RX
PA12.Mode=FDCAN_Activate
PA12.Signal=FDCAN1_TX
PA13.GPIO_Label=TMS
PA13.Mode=Serial_Wire
PA13.Signal=SYS_JTMS-SWDIO
PA14.GPIO_Label=TCK
PA14.Mode=Serial_Wire
PA14.Signal=SYS_JTCK-SWCLK
PA2.GPIO_Label=M1_OPAMP1_OUT
PA2.Signal=SharedAnalog_PA2
PA3.GPIO_Label=M1_OPAMP1_EXT_GAIN
PA3.Mode=Standalone
PA3.Signal=OPAMP1_VINM
PA4.GPIO_Label=BEARING_TEMPERATURE
PA4.Mode=IN17-Single-Ended
PA4.Signal=ADC2_IN17
PA5.Mode=Full_Duplex_Master
PA5.Signal=SPI1_SCK
PA6.GPIO_Label=M1_OPAMP2_OUT
PA6.Signal=SharedAnalog_PA6
PA7.GPIO_Label=M1_CURR_SHUNT_V
PA7.Signal=SharedAnalog_PA7
PA9.GPIO_Label=UART_TX
PA9.GPIO_Mode=GPIO_MODE_AF_PP
PA9.GPIO_PuPd=GPIO_NOPULL
PA9.GPIO_Speed=GPIO_SPEED_FREQ_LOW
PA9.Mode=Asynchronous
PA9.Signal=USART1_TX
PB0.GPIO_Label=M1_CURR_SHUNT_W
PB0.Signal=SharedAnalog_PB0
PB4.Mode=Full_Duplex_Master
PB4.Signal=SPI1_MISO
PB5.Mode=Full_Duplex_Master
PB5.Signal=SPI1_MOSI
PB6.GPIO_Label=M1_ENCODER_A
PB6.Signal=S_TIM4_CH1
PB7.GPIO_Label=M1_ENCODER_B
PB7.Signal=S_TIM4_CH2
PC14-OSC32_IN.GPIO_Label=SEC_IN
PC14-OSC32_IN.Signal=GPIO_Input
PC15-OSC32_OUT.GPIO_Label=SEC_OUT
PC15-OSC32_OUT.Signal=GPIO_Output
PC3.GPIO_Label=ABSOLUTE_ENCODER_CS
PC3.Signal=GPIO_Output
PC4.GPIO_Label=M1_TEMPERATURE
PC4.Mode=IN5-Single-Ended
PC4.Signal=ADC2_IN5
PC5.GPIO_Label=M1_OPAMP2_EXT_GAIN
PC5.Mode=Standalone
PC5.Signal=OPAMP2_VINM
PC8.GPIO_Label=GD_SCL
PC8.Mode=I2C
PC8.Signal=I2C3_SCL
PC9.GPIO_Label=GD_SDA
PC9.Mode=I2C
PC9.Signal=I2C3_SDA
PE10.GPIO_Label=M1_PWM_VL
PE10.GPIO_PuPd=GPIO_PULLUP
PE10.GPIO_Speed=GPIO_SPEED_FREQ_HIGH
PE10.Mode=PWM Generation2 CH2 CH2N
PE10.Signal=TIM1_CH2N
PE11.GPIO_Label=M1_PWM_VH
PE11.GPIO_PuPd=GPIO_PULLDOWN
PE11.GPIO_Speed=GPIO_SPEED_FREQ_HIGH
PE11.Signal=S_TIM1_CH2
PE12.GPIO_Label=M1_PWM_WL
PE12.GPIO_PuPd=GPIO_PULLUP
PE12.GPIO_Speed=GPIO_SPEED_FREQ_HIGH
PE12.Mode=PWM Generation3 CH3 CH3N
PE12.Signal=TIM1_CH3N
PE13.GPIO_Label=M1_PWM_WH
PE13.GPIO_PuPd=GPIO_PULLDOWN
PE13.GPIO_Speed=GPIO_SPEED_FREQ_HIGH
PE13.Signal=S_TIM1_CH3
PE14.GPIO_Label=GD_READY
PE14.GPIO_PuPd=GPIO_PULLUP
PE14.Signal=GPIO_Input
PE15.GPIO_Label=GD_NFAULT
PE15.GPIO_PuPd=GPIO_PULLUP
PE15.Signal=GPIO_Input
PE7.GPIO_Label=GD_WAKE
PE7.PinState=GPIO_PIN_SET
PE7.Signal=GPIO_Output
PE8.GPIO_Label=M1_PWM_UL
PE8.GPIO_PuPd=GPIO_PULLUP
PE8.GPIO_Speed=GPIO_SPEED_FREQ_HIGH
PE8.Mode=PWM Generation1 CH1 CH1N
PE8.Signal=TIM1_CH1N
PE9.GPIO_Label=M1_PWM_UH
PE9.GPIO_PuPd=GPIO_PULLDOWN
PE9.GPIO_Speed=GPIO_SPEED_FREQ_HIGH
PE9.Signal=S_TIM1_CH1
PF0-OSC_IN.Mode=HSE-External-Oscillator
PF0-OSC_IN.Signal=RCC_OSC_IN
PF1-OSC_OUT.Mode=HSE-External-Oscillator
PF1-OSC_OUT.Signal=RCC_OSC_OUT
ProjectManager.HeapSize=0x200
ProjectManager.StackSize=0x400
ProjectManager.TargetToolchain=MDK-ARM V5
RCC.ADC12CLockSelection=RCC_ADC12CLKSOURCE_PLL
RCC.ADC12Freq_Value=42500000
RCC.AHBFreq_Value=170000000
RCC.APB1Freq_Value=170000000
RCC.APB1TimFreq_Value=170000000
RCC.APB2Freq_Value=170000000
RCC.APB2TimFreq_Value=170000000
RCC.CortexFreq_Value=170000000
RCC.EXTERNAL_CLOCK_VALUE=12288000
RCC.EnbaleCSS=true
RCC.HCLKFreq_Value=170000000
RCC.HSE_VALUE=24000000
RCC.HSI48_VALUE=48000000
RCC.HSI_VALUE=16000000
RCC.LSE_VALUE=32768
RCC.PLLM=RCC_PLLM_DIV6
RCC.PLLN=85
RCC.PLLP=RCC_PLLP_DIV8
RCC.PLLSourceVirtual=RCC_PLLSOURCE_HSE
RCC.SYSCLKFreq_VALUE=170000000
RCC.SYSCLKSource=RCC_SYSCLKSOURCE_PLLCLK
RCC.USBFreq_Value=170000000
RCC.VCOOutputFreq_Value=340000000
SH.S_TIM1_CH1.0=TIM1_CH1,PWM Generation1 CH1 CH1N
SH.S_TIM1_CH2.0=TIM1_CH2,PWM Generation2 CH2 CH2N
SH.S_TIM1_CH3.0=TIM1_CH3,PWM Generation3 CH3 CH3N
SH.S_TIM4_CH1.0=TIM4_CH1,Encoder_Interface
SH.S_TIM4_CH2.0=TIM4_CH2,Encoder_Interface
SH.SharedAnalog_PA1.0=COMP1_INP,INP
SH.SharedAnalog_PA1.1=OPAMP1_VINP,Standalone
SH.SharedAnalog_PA2.0=OPAMP1_VOUT,Standalone
SH.SharedAnalog_PA2.1=ADC1_IN3,IN3-Single-Ended
SH.SharedAnalog_PA6.0=OPAMP2_VOUT,Standalone
SH.SharedAnalog_PA6.1=ADC2_IN3,IN3-Single-Ended
SH.SharedAnalog_PA7.0=COMP2_INP,INP
SH.SharedAnalog_PA7.1=OPAMP2_VINP,Standalone
SH.SharedAnalog_PB0.0=OPAMP2_VINP_SEC
SH.SharedAnalog_PB0.1=COMP4_INP,INP
SPI1.BaudRatePrescaler=SPI_BAUDRATEPRESCALER_16
SPI1.CalculateBaudRate=10.625 MBits/s
SPI1.DataSize=SPI_DATASIZE_8BIT
SPI1.Direction=SPI_DIRECTION_2LINES
SPI1.Mode=SPI_MODE_MASTER
SPI1.VirtualType=VM_MASTER
TIM1.AutoReloadPreload=TIM_AUTORELOAD_PRELOAD_DISABLE
TIM1.AutomaticOutput=TIM_AUTOMATICOUTPUT_DISABLE
TIM1.Break2Filter=5
TIM1.Break2Polarity=TIM_BREAK2POLARITY_HIGH
TIM1.Break2State=TIM_BREAK2_ENABLE
TIM1.BreakFilter=0
TIM1.BreakPolarity=TIM_BREAKPOLARITY_HIGH
TIM1.BreakState=TIM_BREAK_DISABLE
TIM1.Channel=TIM_CHANNEL_4
TIM1.Channel-PWM\ Generation1\ CH1\ CH1N=TIM_CHANNEL_1
TIM1.Channel-PWM\ Generation2\ CH2\ CH2N=TIM_CHANNEL_2
TIM1.Channel-PWM\ Generation3\ CH3\ CH3N=TIM_CHANNEL_3
TIM1.Channel-PWM\ Generation4\ No\ Output=TIM_CHANNEL_4
TIM1.ClearInputSource=TIM_CLEARINPUTSOURCE_NONE
TIM1.ClockDivision=TIM_CLOCKDIVISION_DIV2
TIM1.CounterMode=TIM_COUNTERMODE_CENTERALIGNED1
TIM1.DeadTime=((DEAD_TIME_COUNTS) / 2)
TIM1.LockLevel=TIM_LOCKLEVEL_1
TIM1.OCFastMode_PWM=TIM_OCFAST_DISABLE
TIM1.OCIdleState_1=TIM_OCIDLESTATE_RESET
TIM1.OCIdleState_2=TIM_OCIDLESTATE_RESET
TIM1.OCIdleState_3=TIM_OCIDLESTATE_RESET
TIM1.OCIdleState_4=TIM_OCIDLESTATE_RESET
TIM1.OCIdleState_5=TIM_OCIDLESTATE_RESET
TIM1.OCIdleState_6=TIM_OCIDLESTATE_RESET
TIM1.OCMode_PWM-PWM\ Generation1\ CH1\ CH1N=TIM_OCMODE_PWM1
TIM1.OCMode_PWM-PWM\ Generation2\ CH2\ CH2N=TIM_OCMODE_PWM1
TIM1.OCMode_PWM-PWM\ Generation3\ CH3\ CH3N=TIM_OCMODE_PWM1
TIM1.OCMode_PWM-PWM\ Generation4\ No\ Output=TIM_OCMODE_PWM2
TIM1.OCNIdleState_1=TIM_OCNIDLESTATE_SET
TIM1.OCNIdleState_2=TIM_OCNIDLESTATE_SET
TIM1.OCNIdleState_3=TIM_OCNIDLESTATE_SET
TIM1.OCNPolarity_1=TIM_OCNPOLARITY_HIGH
TIM1.OCNPolarity_2=TIM_OCNPOLARITY_HIGH
TIM1.OCNPolarity_3=TIM_OCNPOLARITY_HIGH
TIM1.OCPolarity_1=TIM_OCPOLARITY_HIGH
TIM1.OCPolarity_2=TIM_OCPOLARITY_HIGH
TIM1.OCPolarity_3=TIM_OCPOLARITY_HIGH
TIM1.OCPolarity_4=TIM_OCPOLARITY_HIGH
TIM1.OCPolarity_5=TIM_OCPOLARITY_HIGH
TIM1.OCPolarity_6=TIM_OCPOLARITY_HIGH
TIM1.OffStateIDLEMode=TIM_OSSI_ENABLE
TIM1.OffStateRunMode=TIM_OSSR_ENABLE
TIM1.Period=((PWM_PERIOD_CYCLES) / 2)
TIM1.PeriodNoDither=((PWM_PERIOD_CYCLES) / 2)
TIM1.Prescaler=((TIM_CLOCK_DIVIDER) - 1)
TIM1.Pulse-PWM\ Generation1\ CH1=((PWM_PERIOD_CYCLES) / 4)
TIM1.Pulse-PWM\ Generation2\ CH2=((PWM_PERIOD_CYCLES) / 4)
TIM1.Pulse-PWM\ Generation3\ CH3=((PWM_PERIOD_CYCLES) / 4)
TIM1.Pulse-PWM\ Generation4\ No\ Output=(((PWM_PERIOD_CYCLES) / 2) - (HTMIN))
TIM1.Pulse-PWM\ Generation5\ No\ Output=(((PWM_PERIOD_CYCLES) / 2) + 1)
TIM1.Pulse-PWM\ Generation6\ No\ Output=(((PWM_PERIOD_CYCLES) / 2) + 1)
TIM1.RepetitionCounter=(REP_COUNTER)
TIM1.SourceBRK2COMP1=TIM_BREAKINPUTSOURCE_ENABLE
TIM1.SourceBRK2COMP1Polarity=TIM_BREAKINPUTSOURCE_POLARITY_HIGH
TIM1.SourceBRK2COMP2=TIM_BREAKINPUTSOURCE_ENABLE
TIM1.SourceBRK2COMP2Polarity=TIM_BREAKINPUTSOURCE_POLARITY_HIGH
TIM1.SourceBRK2COMP4=TIM_BREAKINPUTSOURCE_ENABLE
TIM1.SourceBRK2COMP4Polarity=TIM_BREAKINPUTSOURCE_POLARITY_HIGH
TIM1.SourceBRK2DigInput=TIM_BREAKINPUTSOURCE_DISABLE
TIM1.TIM_MasterOutputTrigger=TIM_TRGO_OC4REF
TIM1.TIM_MasterOutputTrigger2=TIM_TRGO2_RESET
TIM1.TIM_MasterSlaveMode=TIM_MASTERSLAVEMODE_DISABLE
TIM1.TIM_SlaveMode=TIM_SLAVEMODE_TRIGGER
TIM4.EncoderMode=TIM_ENCODERMODE_TI12
TIM4.IC1Filter=M1_ENC_IC_FILTER
TIM4.IC1Polarity=TIM_ICPOLARITY_RISING
TIM4.IC2Filter=M1_ENC_IC_FILTER
TIM4.IC2Polarity=TIM_ICPOLARITY_RISING
TIM4.Period=M1_PULSE_NBR
TIM6.PeriodNoDither=16999
TIM7.PeriodNoDither=16999
TIM7.Prescaler=9
USART1.BaudRate=1843200
USART1.VirtualMode-Asynchronous=VM_ASYNC
USART1.WordLength=WORDLENGTH_8B
VP_COMP1_VS_VREFINT14.Mode=VREFINT_14
VP_COMP2_VS_VREFINT14.Mode=VREFINT_14
VP_COMP4_VS_VREFINT14.Mode=VREFINT_14
VP_CORDIC_VS_CORDIC.Mode=CORDIC_Activate
VP_MotorControl_MC_ENABLED.Mode=Enabled
VP_SYS_VS_DBSignals.Mode=DisableDeadBatterySignals
VP_TIM1_VS_ClockSourceITR.Mode=TriggerSource_ITR1
VP_TIM1_VS_ControllerModeTrigger.Mode=Trigger Mode
VP_TIM1_VS_no_output4.Mode=PWM Generation4 No Output
VP_TIM6_VS_ClockSourceINT.Mode=Enable_Timer
VP_TIM7_VS_ClockSourceINT.Mode=Enable_Timer
board=custom

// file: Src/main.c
/* USER CODE BEGIN Header */
/**
  ******************************************************************************
  * @file           : main.c
  * @brief          : Main program body
  ******************************************************************************
  * @attention
  *
  * <h2><center>&copy; Copyright (c) 2022 STMicroelectronics.
  * All rights reserved.</center></h2>
  *
  * This software component is licensed by ST under Ultimate Liberty license
  * SLA0044, the "License"; You may not use this file except in compliance with
  * the License. You may obtain a copy of the License at:
  *                             www.st.com/SLA0044
  *
  ******************************************************************************
  */
/* USER CODE END Header */
#include "main.h"

/* USER CODE BEGIN Includes */
#include "universal_joint.h"

/* USER CODE END Includes */

ADC_HandleTypeDef hadc1;
ADC_HandleTypeDef hadc2;

COMP_HandleTypeDef hcomp1;
COMP_HandleTypeDef hcomp2;
COMP_HandleTypeDef hcomp4;

CORDIC_HandleTypeDef hcordic;

FDCAN_HandleTypeDef hfdcan1;

I2C_HandleTypeDef hi2c3;

OPAMP_HandleTypeDef hopamp1;
OPAMP_HandleTypeDef hopamp2;

SPI_HandleTypeDef hspi1;
DMA_HandleTypeDef hdma_spi1_rx;
DMA_HandleTypeDef hdma_spi1_tx;

TIM_HandleTypeDef htim1;
TIM_HandleTypeDef htim4;
TIM_HandleTypeDef htim6;
TIM_HandleTypeDef htim7;

UART_HandleTypeDef huart1;
DMA_HandleTypeDef hdma_usart1_rx;
DMA_HandleTypeDef hdma_usart1_tx;

/* USER CODE BEGIN PV */
extern Counters_Handle_t volatile g_counters;
uint8_t g_reg_80;

/* USER CODE END PV */

void SystemClock_Config(void);
static void MX_GPIO_Init(void);
static void MX_DMA_Init(void);
static void MX_ADC1_Init(void);
static void MX_ADC2_Init(void);
static void MX_COMP1_Init(void);
static void MX_COMP2_Init(void);
static void MX_COMP4_Init(void);
static void MX_CORDIC_Init(void);
static void MX_I2C3_Init(void);
static void MX_OPAMP1_Init(void);
static void MX_OPAMP2_Init(void);
static void MX_TIM1_Init(void);
static void MX_TIM4_Init(void);
static void MX_USART1_UART_Init(void);
static void MX_FDCAN1_Init(void);
static void MX_SPI1_Init(void);
static void MX_TIM6_Init(void);
static void MX_TIM7_Init(void);
static void MX_NVIC_Init(void);

int main(void)
{

  /* MCU Configuration--------------------------------------------------------*/

  /* Reset of all peripherals, Initializes the Flash interface and the Systick. */
  HAL_Init();

  /* Configure the system clock */
  SystemClock_Config();

  /* Initialize all configured peripherals */
  MX_GPIO_Init();
  MX_DMA_Init();
  MX_ADC1_Init();
  MX_ADC2_Init();
  MX_COMP1_Init();
  MX_COMP2_Init();
  MX_COMP4_Init();
  MX_CORDIC_Init();
  MX_I2C3_Init();
  MX_OPAMP1_Init();
  MX_OPAMP2_Init();
  MX_TIM1_Init();
  MX_TIM4_Init();
  MX_USART1_UART_Init();
  MX_MotorControl_Init();
  MX_FDCAN1_Init();
  MX_SPI1_Init();
  MX_TIM6_Init();
  MX_TIM7_Init();

  /* Initialize interrupts */
  MX_NVIC_Init();
  /* USER CODE BEGIN 2 */
	UJ_Init();

  /* USER CODE END 2 */

  /* Infinite loop */
  while (1)
  {

    /* USER CODE BEGIN 3 */
		g_counters.main_loop++;
		g_counters.can_tx_free_level = HAL_FDCAN_GetTxFifoFreeLevel(&hfdcan1);
		g_counters.can_rx_fill_level = HAL_FDCAN_GetRxFifoFillLevel(&hfdcan1, FDCAN_RX_FIFO0);

  }
  /* USER CODE END 3 */
}

void SystemClock_Config(void)
{
  RCC_OscInitTypeDef RCC_OscInitStruct = {0};
  RCC_ClkInitTypeDef RCC_ClkInitStruct = {0};
  RCC_PeriphCLKInitTypeDef PeriphClkInit = {0};

  /** Configure the main internal regulator output voltage
  */
  HAL_PWREx_ControlVoltageScaling(PWR_REGULATOR_VOLTAGE_SCALE1_BOOST);
  /** Initializes the RCC Oscillators according to the specified parameters
  * in the RCC_OscInitTypeDef structure.
  */
  RCC_OscInitStruct.OscillatorType = RCC_OSCILLATORTYPE_HSE;
  RCC_OscInitStruct.HSEState = RCC_HSE_ON;
  RCC_OscInitStruct.PLL.PLLState = RCC_PLL_ON;
  RCC_OscInitStruct.PLL.PLLSource = RCC_PLLSOURCE_HSE;
  RCC_OscInitStruct.PLL.PLLM = RCC_PLLM_DIV6;
  RCC_OscInitStruct.PLL.PLLN = 85;
  RCC_OscInitStruct.PLL.PLLP = RCC_PLLP_DIV8;
  RCC_OscInitStruct.PLL.PLLQ = RCC_PLLQ_DIV2;
  RCC_OscInitStruct.PLL.PLLR = RCC_PLLR_DIV2;
  if (HAL_RCC_OscConfig(&RCC_OscInitStruct) != HAL_OK)
  {
    Error_Handler();
  }
  /** Initializes the CPU, AHB and APB buses clocks
  */
  RCC_ClkInitStruct.ClockType = RCC_CLOCKTYPE_HCLK|RCC_CLOCKTYPE_SYSCLK
                              |RCC_CLOCKTYPE_PCLK1|RCC_CLOCKTYPE_PCLK2;
  RCC_ClkInitStruct.SYSCLKSource = RCC_SYSCLKSOURCE_PLLCLK;
  RCC_ClkInitStruct.AHBCLKDivider = RCC_SYSCLK_DIV1;
  RCC_ClkInitStruct.APB1CLKDivider = RCC_HCLK_DIV1;
  RCC_ClkInitStruct.APB2CLKDivider = RCC_HCLK_DIV1;

  if (HAL_RCC_ClockConfig(&RCC_ClkInitStruct, FLASH_LATENCY_4) != HAL_OK)
  {
    Error_Handler();
  }
  /** Initializes the peripherals clocks
  */
  PeriphClkInit.PeriphClockSelection = RCC_PERIPHCLK_USART1|RCC_PERIPHCLK_I2C3
                              |RCC_PERIPHCLK_ADC12|RCC_PERIPHCLK_FDCAN;
  PeriphClkInit.Usart1ClockSelection = RCC_USART1CLKSOURCE_PCLK2;
  PeriphClkInit.I2c3ClockSelection = RCC_I2C3CLKSOURCE_PCLK1;
  PeriphClkInit.FdcanClockSelection = RCC_FDCANCLKSOURCE_PCLK1;
  PeriphClkInit.Adc12ClockSelection = RCC_ADC12CLKSOURCE_PLL;
  if (HAL_RCCEx_PeriphCLKConfig(&PeriphClkInit) != HAL_OK)
  {
    Error_Handler();
  }
  /** Enables the Clock Security System
  */
  HAL_RCC_EnableCSS();
}

/**
  * @brief NVIC Configuration.
  * @retval None
  */
static void MX_NVIC_Init(void)
{
  /* TIM1_BRK_TIM15_IRQn interrupt configuration */
  HAL_NVIC_SetPriority(TIM1_BRK_TIM15_IRQn, 4, 1);
  HAL_NVIC_EnableIRQ(TIM1_BRK_TIM15_IRQn);
  /* TIM1_UP_TIM16_IRQn interrupt configuration */
  HAL_NVIC_SetPriority(TIM1_UP_TIM16_IRQn, 0, 0);
  HAL_NVIC_EnableIRQ(TIM1_UP_TIM16_IRQn);
  /* ADC1_2_IRQn interrupt configuration */
  HAL_NVIC_SetPriority(ADC1_2_IRQn, 2, 0);
  HAL_NVIC_EnableIRQ(ADC1_2_IRQn);
  /* TIM4_IRQn interrupt configuration */
  HAL_NVIC_SetPriority(TIM4_IRQn, 3, 0);
  HAL_NVIC_EnableIRQ(TIM4_IRQn);
  /* USART1_IRQn interrupt configuration */
  HAL_NVIC_SetPriority(USART1_IRQn, 3, 1);
  HAL_NVIC_EnableIRQ(USART1_IRQn);
  /* DMA1_Channel2_IRQn interrupt configuration */
  HAL_NVIC_SetPriority(DMA1_Channel2_IRQn, 0, 0);
  HAL_NVIC_EnableIRQ(DMA1_Channel2_IRQn);
}

static void MX_ADC1_Init(void)
{

  ADC_MultiModeTypeDef multimode = {0};
  ADC_InjectionConfTypeDef sConfigInjected = {0};
  ADC_ChannelConfTypeDef sConfig = {0};

  /** Common config
  */
  hadc1.Instance = ADC1;
  hadc1.Init.ClockPrescaler = ADC_CLOCK_ASYNC_DIV1;
  hadc1.Init.Resolution = ADC_RESOLUTION_12B;
  hadc1.Init.DataAlign = ADC_DATAALIGN_LEFT;
  hadc1.Init.GainCompensation = 0;
  hadc1.Init.ScanConvMode = ADC_SCAN_DISABLE;
  hadc1.Init.EOCSelection = ADC_EOC_SINGLE_CONV;
  hadc1.Init.LowPowerAutoWait = DISABLE;
  hadc1.Init.ContinuousConvMode = DISABLE;
  hadc1.Init.NbrOfConversion = 1;
  hadc1.Init.DiscontinuousConvMode = DISABLE;
  hadc1.Init.ExternalTrigConv = ADC_SOFTWARE_START;
  hadc1.Init.ExternalTrigConvEdge = ADC_EXTERNALTRIGCONVEDGE_NONE;
  hadc1.Init.DMAContinuousRequests = DISABLE;
  hadc1.Init.Overrun = ADC_OVR_DATA_PRESERVED;
  hadc1.Init.OversamplingMode = DISABLE;
  if (HAL_ADC_Init(&hadc1) != HAL_OK)
  {
    Error_Handler();
  }
  /** Configure the ADC multi-mode
  */
  multimode.Mode = ADC_MODE_INDEPENDENT;
  if (HAL_ADCEx_MultiModeConfigChannel(&hadc1, &multimode) != HAL_OK)
  {
    Error_Handler();
  }
  /** Configure Injected Channel
  */
  sConfigInjected.InjectedChannel = ADC_CHANNEL_3;
  sConfigInjected.InjectedRank = ADC_INJECTED_RANK_1;
  sConfigInjected.InjectedSamplingTime = ADC_SAMPLETIME_6CYCLES_5;
  sConfigInjected.InjectedSingleDiff = ADC_SINGLE_ENDED;
  sConfigInjected.InjectedOffsetNumber = ADC_OFFSET_NONE;
  sConfigInjected.InjectedOffset = 0;
  sConfigInjected.InjectedNbrOfConversion = 1;
  sConfigInjected.InjectedDiscontinuousConvMode = DISABLE;
  sConfigInjected.AutoInjectedConv = DISABLE;
  sConfigInjected.QueueInjectedContext = DISABLE;
  sConfigInjected.ExternalTrigInjecConv = ADC_EXTERNALTRIGINJEC_T1_TRGO;
  sConfigInjected.ExternalTrigInjecConvEdge = ADC_EXTERNALTRIGINJECCONV_EDGE_RISING;
  sConfigInjected.InjecOversamplingMode = DISABLE;
  if (HAL_ADCEx_InjectedConfigChannel(&hadc1, &sConfigInjected) != HAL_OK)
  {
    Error_Handler();
  }
  /** Configure Regular Channel
  */
  sConfig.Channel = ADC_CHANNEL_1;
  sConfig.Rank = ADC_REGULAR_RANK_1;
  sConfig.SamplingTime = ADC_SAMPLETIME_47CYCLES_5;
  sConfig.SingleDiff = ADC_SINGLE_ENDED;
  sConfig.OffsetNumber = ADC_OFFSET_NONE;
  sConfig.Offset = 0;
  if (HAL_ADC_ConfigChannel(&hadc1, &sConfig) != HAL_OK)
  {
    Error_Handler();
  }

}

static void MX_ADC2_Init(void)
{

  ADC_InjectionConfTypeDef sConfigInjected = {0};
  ADC_ChannelConfTypeDef sConfig = {0};

  /** Common config
  */
  hadc2.Instance = ADC2;
  hadc2.Init.ClockPrescaler = ADC_CLOCK_ASYNC_DIV1;
  hadc2.Init.Resolution = ADC_RESOLUTION_12B;
  hadc2.Init.DataAlign = ADC_DATAALIGN_LEFT;
  hadc2.Init.GainCompensation = 0;
  hadc2.Init.ScanConvMode = ADC_SCAN_ENABLE;
  hadc2.Init.EOCSelection = ADC_EOC_SINGLE_CONV;
  hadc2.Init.LowPowerAutoWait = DISABLE;
  hadc2.Init.ContinuousConvMode = DISABLE;
  hadc2.Init.NbrOfConversion = 2;
  hadc2.Init.DiscontinuousConvMode = DISABLE;
  hadc2.Init.ExternalTrigConv = ADC_SOFTWARE_START;
  hadc2.Init.ExternalTrigConvEdge = ADC_EXTERNALTRIGCONVEDGE_NONE;
  hadc2.Init.DMAContinuousRequests = DISABLE;
  hadc2.Init.Overrun = ADC_OVR_DATA_PRESERVED;
  hadc2.Init.OversamplingMode = DISABLE;
  if (HAL_ADC_Init(&hadc2) != HAL_OK)
  {
    Error_Handler();
  }
  /** Configure Injected Channel
  */
  sConfigInjected.InjectedChannel = ADC_CHANNEL_3;
  sConfigInjected.InjectedRank = ADC_INJECTED_RANK_1;
  sConfigInjected.InjectedSamplingTime = ADC_SAMPLETIME_6CYCLES_5;
  sConfigInjected.InjectedSingleDiff = ADC_SINGLE_ENDED;
  sConfigInjected.InjectedOffsetNumber = ADC_OFFSET_NONE;
  sConfigInjected.InjectedOffset = 0;
  sConfigInjected.InjectedNbrOfConversion = 1;
  sConfigInjected.InjectedDiscontinuousConvMode = DISABLE;
  sConfigInjected.AutoInjectedConv = DISABLE;
  sConfigInjected.QueueInjectedContext = DISABLE;
  sConfigInjected.ExternalTrigInjecConv = ADC_EXTERNALTRIGINJEC_T1_TRGO;
  sConfigInjected.ExternalTrigInjecConvEdge = ADC_EXTERNALTRIGINJECCONV_EDGE_RISING;
  sConfigInjected.InjecOversamplingMode = DISABLE;
  if (HAL_ADCEx_InjectedConfigChannel(&hadc2, &sConfigInjected) != HAL_OK)
  {
    Error_Handler();
  }
  /** Configure Regular Channel
  */
  sConfig.Channel = ADC_CHANNEL_5;
  sConfig.Rank = ADC_REGULAR_RANK_1;
  sConfig.SamplingTime = ADC_SAMPLETIME_47CYCLES_5;
  sConfig.SingleDiff = ADC_SINGLE_ENDED;
  sConfig.OffsetNumber = ADC_OFFSET_NONE;
  sConfig.Offset = 0;
  if (HAL_ADC_ConfigChannel(&hadc2, &sConfig) != HAL_OK)
  {
    Error_Handler();
  }
  /** Configure Regular Channel
  */
  sConfig.Channel = ADC_CHANNEL_17;
  sConfig.Rank = ADC_REGULAR_RANK_2;
  if (HAL_ADC_ConfigChannel(&hadc2, &sConfig) != HAL_OK)
  {
    Error_Handler();
  }

}

static void MX_COMP1_Init(void)
{

  hcomp1.Instance = COMP1;
  hcomp1.Init.InputPlus = COMP_INPUT_PLUS_IO1;
  hcomp1.Init.InputMinus = COMP_INPUT_MINUS_1_4VREFINT;
  hcomp1.Init.OutputPol = COMP_OUTPUTPOL_NONINVERTED;
  hcomp1.Init.Hysteresis = COMP_HYSTERESIS_NONE;
  hcomp1.Init.BlankingSrce = COMP_BLANKINGSRC_NONE;
  hcomp1.Init.TriggerMode = COMP_TRIGGERMODE_NONE;
  if (HAL_COMP_Init(&hcomp1) != HAL_OK)
  {
    Error_Handler();
  }

}

static void MX_COMP2_Init(void)
{

  hcomp2.Instance = COMP2;
  hcomp2.Init.InputPlus = COMP_INPUT_PLUS_IO1;
  hcomp2.Init.InputMinus = COMP_INPUT_MINUS_1_4VREFINT;
  hcomp2.Init.OutputPol = COMP_OUTPUTPOL_NONINVERTED;
  hcomp2.Init.Hysteresis = COMP_HYSTERESIS_NONE;
  hcomp2.Init.BlankingSrce = COMP_BLANKINGSRC_NONE;
  hcomp2.Init.TriggerMode = COMP_TRIGGERMODE_NONE;
  if (HAL_COMP_Init(&hcomp2) != HAL_OK)
  {
    Error_Handler();
  }

}

static void MX_COMP4_Init(void)
{

  hcomp4.Instance = COMP4;
  hcomp4.Init.InputPlus = COMP_INPUT_PLUS_IO1;
  hcomp4.Init.InputMinus = COMP_INPUT_MINUS_1_4VREFINT;
  hcomp4.Init.OutputPol = COMP_OUTPUTPOL_NONINVERTED;
  hcomp4.Init.Hysteresis = COMP_HYSTERESIS_NONE;
  hcomp4.Init.BlankingSrce = COMP_BLANKINGSRC_NONE;
  hcomp4.Init.TriggerMode = COMP_TRIGGERMODE_NONE;
  if (HAL_COMP_Init(&hcomp4) != HAL_OK)
  {
    Error_Handler();
  }

}

static void MX_CORDIC_Init(void)
{

  hcordic.Instance = CORDIC;
  if (HAL_CORDIC_Init(&hcordic) != HAL_OK)
  {
    Error_Handler();
  }

}

static void MX_FDCAN1_Init(void)
{

  hfdcan1.Instance = FDCAN1;
  hfdcan1.Init.ClockDivider = FDCAN_CLOCK_DIV2;
  hfdcan1.Init.FrameFormat = FDCAN_FRAME_FD_BRS;
  hfdcan1.Init.Mode = FDCAN_MODE_NORMAL;
  hfdcan1.Init.AutoRetransmission = ENABLE;
  hfdcan1.Init.TransmitPause = ENABLE;
  hfdcan1.Init.ProtocolException = DISABLE;
  hfdcan1.Init.NominalPrescaler = 5;
  hfdcan1.Init.NominalSyncJumpWidth = 2;
  hfdcan1.Init.NominalTimeSeg1 = 12;
  hfdcan1.Init.NominalTimeSeg2 = 4;
  hfdcan1.Init.DataPrescaler = 1;
  hfdcan1.Init.DataSyncJumpWidth = 2;
  hfdcan1.Init.DataTimeSeg1 = 12;
  hfdcan1.Init.DataTimeSeg2 = 4;
  hfdcan1.Init.StdFiltersNbr = 2;
  hfdcan1.Init.ExtFiltersNbr = 0;
  hfdcan1.Init.TxFifoQueueMode = FDCAN_TX_FIFO_OPERATION;
  if (HAL_FDCAN_Init(&hfdcan1) != HAL_OK)
  {
    Error_Handler();
  }

}

static void MX_I2C3_Init(void)
{

  hi2c3.Instance = I2C3;
  hi2c3.Init.Timing = 0x00802172;
  hi2c3.Init.OwnAddress1 = 0;
  hi2c3.Init.AddressingMode = I2C_ADDRESSINGMODE_7BIT;
  hi2c3.Init.DualAddressMode = I2C_DUALADDRESS_DISABLE;
  hi2c3.Init.OwnAddress2 = 0;
  hi2c3.Init.OwnAddress2Masks = I2C_OA2_NOMASK;
  hi2c3.Init.GeneralCallMode = I2C_GENERALCALL_DISABLE;
  hi2c3.Init.NoStretchMode = I2C_NOSTRETCH_DISABLE;
  if (HAL_I2C_Init(&hi2c3) != HAL_OK)
  {
    Error_Handler();
  }
  /** Configure Analogue filter
  */
  if (HAL_I2CEx_ConfigAnalogFilter(&hi2c3, I2C_ANALOGFILTER_ENABLE) != HAL_OK)
  {
    Error_Handler();
  }
  /** Configure Digital filter
  */
  if (HAL_I2CEx_ConfigDigitalFilter(&hi2c3, 0) != HAL_OK)
  {
    Error_Handler();
  }
  /** I2C Fast mode Plus enable
  */
  __HAL_SYSCFG_FASTMODEPLUS_ENABLE(I2C_FASTMODEPLUS_I2C3);

}

static void MX_OPAMP1_Init(void)
{

  hopamp1.Instance = OPAMP1;
  hopamp1.Init.PowerMode = OPAMP_POWERMODE_NORMALSPEED;
  hopamp1.Init.Mode = OPAMP_STANDALONE_MODE;
  hopamp1.Init.InvertingInput = OPAMP_INVERTINGINPUT_IO0;
  hopamp1.Init.NonInvertingInput = OPAMP_NONINVERTINGINPUT_IO0;
  hopamp1.Init.InternalOutput = DISABLE;
  hopamp1.Init.TimerControlledMuxmode = OPAMP_TIMERCONTROLLEDMUXMODE_DISABLE;
  hopamp1.Init.UserTrimming = OPAMP_TRIMMING_FACTORY;
  if (HAL_OPAMP_Init(&hopamp1) != HAL_OK)
  {
    Error_Handler();
  }

}

static void MX_OPAMP2_Init(void)
{

  hopamp2.Instance = OPAMP2;
  hopamp2.Init.PowerMode = OPAMP_POWERMODE_NORMALSPEED;
  hopamp2.Init.Mode = OPAMP_STANDALONE_MODE;
  hopamp2.Init.InvertingInput = OPAMP_INVERTINGINPUT_IO1;
  hopamp2.Init.NonInvertingInput = OPAMP_NONINVERTINGINPUT_IO0;
  hopamp2.Init.InternalOutput = DISABLE;
  hopamp2.Init.TimerControlledMuxmode = OPAMP_TIMERCONTROLLEDMUXMODE_DISABLE;
  hopamp2.Init.UserTrimming = OPAMP_TRIMMING_FACTORY;
  if (HAL_OPAMP_Init(&hopamp2) != HAL_OK)
  {
    Error_Handler();
  }

}

static void MX_SPI1_Init(void)
{

  /* SPI1 parameter configuration*/
  hspi1.Instance = SPI1;
  hspi1.Init.Mode = SPI_MODE_MASTER;
  hspi1.Init.Direction = SPI_DIRECTION_2LINES;
  hspi1.Init.DataSize = SPI_DATASIZE_8BIT;
  hspi1.Init.CLKPolarity = SPI_POLARITY_LOW;
  hspi1.Init.CLKPhase = SPI_PHASE_1EDGE;
  hspi1.Init.NSS = SPI_NSS_SOFT;
  hspi1.Init.BaudRatePrescaler = SPI_BAUDRATEPRESCALER_16;
  hspi1.Init.FirstBit = SPI_FIRSTBIT_MSB;
  hspi1.Init.TIMode = SPI_TIMODE_DISABLE;
  hspi1.Init.CRCCalculation = SPI_CRCCALCULATION_DISABLE;
  hspi1.Init.CRCPolynomial = 7;
  hspi1.Init.CRCLength = SPI_CRC_LENGTH_DATASIZE;
  hspi1.Init.NSSPMode = SPI_NSS_PULSE_ENABLE;
  if (HAL_SPI_Init(&hspi1) != HAL_OK)
  {
    Error_Handler();
  }

}

static void MX_TIM1_Init(void)
{

  TIM_SlaveConfigTypeDef sSlaveConfig = {0};
  TIM_MasterConfigTypeDef sMasterConfig = {0};
  TIMEx_BreakInputConfigTypeDef sBreakInputConfig = {0};
  TIM_OC_InitTypeDef sConfigOC = {0};
  TIM_BreakDeadTimeConfigTypeDef sBreakDeadTimeConfig = {0};

  htim1.Instance = TIM1;
  htim1.Init.Prescaler = ((TIM_CLOCK_DIVIDER) - 1);
  htim1.Init.CounterMode = TIM_COUNTERMODE_CENTERALIGNED1;
  htim1.Init.Period = ((PWM_PERIOD_CYCLES) / 2);
  htim1.Init.ClockDivision = TIM_CLOCKDIVISION_DIV2;
  htim1.Init.RepetitionCounter = (REP_COUNTER);
  htim1.Init.AutoReloadPreload = TIM_AUTORELOAD_PRELOAD_DISABLE;
  if (HAL_TIM_Base_Init(&htim1) != HAL_OK)
  {
    Error_Handler();
  }
  if (HAL_TIM_PWM_Init(&htim1) != HAL_OK)
  {
    Error_Handler();
  }
  sSlaveConfig.SlaveMode = TIM_SLAVEMODE_TRIGGER;
  sSlaveConfig.InputTrigger = TIM_TS_ITR1;
  if (HAL_TIM_SlaveConfigSynchro(&htim1, &sSlaveConfig) != HAL_OK)
  {
    Error_Handler();
  }
  sMasterConfig.MasterOutputTrigger = TIM_TRGO_OC4REF;
  sMasterConfig.MasterOutputTrigger2 = TIM_TRGO2_RESET;
  sMasterConfig.MasterSlaveMode = TIM_MASTERSLAVEMODE_DISABLE;
  if (HAL_TIMEx_MasterConfigSynchronization(&htim1, &sMasterConfig) != HAL_OK)
  {
    Error_Handler();
  }
  sBreakInputConfig.Source = TIM_BREAKINPUTSOURCE_COMP1;
  sBreakInputConfig.Enable = TIM_BREAKINPUTSOURCE_ENABLE;
  sBreakInputConfig.Polarity = TIM_BREAKINPUTSOURCE_POLARITY_HIGH;
  if (HAL_TIMEx_ConfigBreakInput(&htim1, TIM_BREAKINPUT_BRK2, &sBreakInputConfig) != HAL_OK)
  {
    Error_Handler();
  }
  sBreakInputConfig.Source = TIM_BREAKINPUTSOURCE_COMP2;
  if (HAL_TIMEx_ConfigBreakInput(&htim1, TIM_BREAKINPUT_BRK2, &sBreakInputConfig) != HAL_OK)
  {
    Error_Handler();
  }
  sBreakInputConfig.Source = TIM_BREAKINPUTSOURCE_COMP4;
  if (HAL_TIMEx_ConfigBreakInput(&htim1, TIM_BREAKINPUT_BRK2, &sBreakInputConfig) != HAL_OK)
  {
    Error_Handler();
  }
  sConfigOC.OCMode = TIM_OCMODE_PWM1;
  sConfigOC.Pulse = 0;
  sConfigOC.OCPolarity = TIM_OCPOLARITY_HIGH;
  sConfigOC.OCNPolarity = TIM_OCNPOLARITY_HIGH;
  sConfigOC.OCFastMode = TIM_OCFAST_DISABLE;
  sConfigOC.OCIdleState = TIM_OCIDLESTATE_RESET;
  sConfigOC.OCNIdleState = TIM_OCNIDLESTATE_SET;
  if (HAL_TIM_PWM_ConfigChannel(&htim1, &sConfigOC, TIM_CHANNEL_1) != HAL_OK)
  {
    Error_Handler();
  }
  if (HAL_TIM_PWM_ConfigChannel(&htim1, &sConfigOC, TIM_CHANNEL_2) != HAL_OK)
  {
    Error_Handler();
  }
  if (HAL_TIM_PWM_ConfigChannel(&htim1, &sConfigOC, TIM_CHANNEL_3) != HAL_OK)
  {
    Error_Handler();
  }
  sConfigOC.OCMode = TIM_OCMODE_PWM2;
  sConfigOC.OCNIdleState = TIM_OCNIDLESTATE_RESET;
  if (HAL_TIM_PWM_ConfigChannel(&htim1, &sConfigOC, TIM_CHANNEL_4) != HAL_OK)
  {
    Error_Handler();
  }
  sBreakDeadTimeConfig.OffStateRunMode = TIM_OSSR_ENABLE;
  sBreakDeadTimeConfig.OffStateIDLEMode = TIM_OSSI_ENABLE;
  sBreakDeadTimeConfig.LockLevel = TIM_LOCKLEVEL_1;
  sBreakDeadTimeConfig.DeadTime = ((DEAD_TIME_COUNTS) / 2);
  sBreakDeadTimeConfig.BreakState = TIM_BREAK_DISABLE;
  sBreakDeadTimeConfig.BreakPolarity = TIM_BREAKPOLARITY_HIGH;
  sBreakDeadTimeConfig.BreakFilter = 0;
  sBreakDeadTimeConfig.BreakAFMode = TIM_BREAK_AFMODE_INPUT;
  sBreakDeadTimeConfig.Break2State = TIM_BREAK2_ENABLE;
  sBreakDeadTimeConfig.Break2Polarity = TIM_BREAK2POLARITY_HIGH;
  sBreakDeadTimeConfig.Break2Filter = 5;
  sBreakDeadTimeConfig.Break2AFMode = TIM_BREAK_AFMODE_INPUT;
  sBreakDeadTimeConfig.AutomaticOutput = TIM_AUTOMATICOUTPUT_DISABLE;
  if (HAL_TIMEx_ConfigBreakDeadTime(&htim1, &sBreakDeadTimeConfig) != HAL_OK)
  {
    Error_Handler();
  }
  HAL_TIM_MspPostInit(&htim1);

}

static void MX_TIM4_Init(void)
{

  TIM_Encoder_InitTypeDef sConfig = {0};
  TIM_MasterConfigTypeDef sMasterConfig = {0};

  htim4.Instance = TIM4;
  htim4.Init.Prescaler = 0;
  htim4.Init.CounterMode = TIM_COUNTERMODE_UP;
  htim4.Init.Period = M1_PULSE_NBR;
  htim4.Init.ClockDivision = TIM_CLOCKDIVISION_DIV1;
  htim4.Init.AutoReloadPreload = TIM_AUTORELOAD_PRELOAD_DISABLE;
  sConfig.EncoderMode = TIM_ENCODERMODE_TI12;
  sConfig.IC1Polarity = TIM_ICPOLARITY_RISING;
  sConfig.IC1Selection = TIM_ICSELECTION_DIRECTTI;
  sConfig.IC1Prescaler = TIM_ICPSC_DIV1;
  sConfig.IC1Filter = M1_ENC_IC_FILTER;
  sConfig.IC2Polarity = TIM_ICPOLARITY_RISING;
  sConfig.IC2Selection = TIM_ICSELECTION_DIRECTTI;
  sConfig.IC2Prescaler = TIM_ICPSC_DIV1;
  sConfig.IC2Filter = M1_ENC_IC_FILTER;
  if (HAL_TIM_Encoder_Init(&htim4, &sConfig) != HAL_OK)
  {
    Error_Handler();
  }
  sMasterConfig.MasterOutputTrigger = TIM_TRGO_RESET;
  sMasterConfig.MasterSlaveMode = TIM_MASTERSLAVEMODE_DISABLE;
  if (HAL_TIMEx_MasterConfigSynchronization(&htim4, &sMasterConfig) != HAL_OK)
  {
    Error_Handler();
  }

}

static void MX_TIM6_Init(void)
{

  TIM_MasterConfigTypeDef sMasterConfig = {0};

  htim6.Instance = TIM6;
  htim6.Init.Prescaler = 0;
  htim6.Init.CounterMode = TIM_COUNTERMODE_UP;
  htim6.Init.Period = 16999;
  htim6.Init.AutoReloadPreload = TIM_AUTORELOAD_PRELOAD_DISABLE;
  if (HAL_TIM_Base_Init(&htim6) != HAL_OK)
  {
    Error_Handler();
  }
  sMasterConfig.MasterOutputTrigger = TIM_TRGO_RESET;
  sMasterConfig.MasterSlaveMode = TIM_MASTERSLAVEMODE_DISABLE;
  if (HAL_TIMEx_MasterConfigSynchronization(&htim6, &sMasterConfig) != HAL_OK)
  {
    Error_Handler();
  }

}

static void MX_TIM7_Init(void)
{

  TIM_MasterConfigTypeDef sMasterConfig = {0};

  htim7.Instance = TIM7;
  htim7.Init.Prescaler = 9;
  htim7.Init.CounterMode = TIM_COUNTERMODE_UP;
  htim7.Init.Period = 16999;
  htim7.Init.AutoReloadPreload = TIM_AUTORELOAD_PRELOAD_DISABLE;
  if (HAL_TIM_Base_Init(&htim7) != HAL_OK)
  {
    Error_Handler();
  }
  sMasterConfig.MasterOutputTrigger = TIM_TRGO_RESET;
  sMasterConfig.MasterSlaveMode = TIM_MASTERSLAVEMODE_DISABLE;
  if (HAL_TIMEx_MasterConfigSynchronization(&htim7, &sMasterConfig) != HAL_OK)
  {
    Error_Handler();
  }

}

static void MX_USART1_UART_Init(void)
{

  huart1.Instance = USART1;
  huart1.Init.BaudRate = 1843200;
  huart1.Init.WordLength = UART_WORDLENGTH_8B;
  huart1.Init.StopBits = UART_STOPBITS_1;
  huart1.Init.Parity = UART_PARITY_NONE;
  huart1.Init.Mode = UART_MODE_TX_RX;
  huart1.Init.HwFlowCtl = UART_HWCONTROL_NONE;
  huart1.Init.OverSampling = UART_OVERSAMPLING_16;
  huart1.Init.OneBitSampling = UART_ONE_BIT_SAMPLE_DISABLE;
  huart1.Init.ClockPrescaler = UART_PRESCALER_DIV1;
  huart1.AdvancedInit.AdvFeatureInit = UART_ADVFEATURE_NO_INIT;
  if (HAL_UART_Init(&huart1) != HAL_OK)
  {
    Error_Handler();
  }
  if (HAL_UARTEx_SetTxFifoThreshold(&huart1, UART_TXFIFO_THRESHOLD_1_8) != HAL_OK)
  {
    Error_Handler();
  }
  if (HAL_UARTEx_SetRxFifoThreshold(&huart1, UART_RXFIFO_THRESHOLD_1_8) != HAL_OK)
  {
    Error_Handler();
  }
  if (HAL_UARTEx_DisableFifoMode(&huart1) != HAL_OK)
  {
    Error_Handler();
  }

}

static void MX_DMA_Init(void)
{

  /* DMA controller clock enable */
  __HAL_RCC_DMAMUX1_CLK_ENABLE();
  __HAL_RCC_DMA1_CLK_ENABLE();

  /* DMA interrupt init */
  /* DMA1_Channel1_IRQn interrupt configuration */
  HAL_NVIC_SetPriority(DMA1_Channel1_IRQn, 7, 1);
  HAL_NVIC_EnableIRQ(DMA1_Channel1_IRQn);
  /* DMA1_Channel4_IRQn interrupt configuration */
  HAL_NVIC_SetPriority(DMA1_Channel4_IRQn, 7, 1);
  HAL_NVIC_EnableIRQ(DMA1_Channel4_IRQn);

}

static void MX_GPIO_Init(void)
{
  GPIO_InitTypeDef GPIO_InitStruct = {0};

  /* GPIO Ports Clock Enable */
  __HAL_RCC_GPIOC_CLK_ENABLE();
  __HAL_RCC_GPIOF_CLK_ENABLE();
  __HAL_RCC_GPIOA_CLK_ENABLE();
  __HAL_RCC_GPIOB_CLK_ENABLE();
  __HAL_RCC_GPIOE_CLK_ENABLE();

  /*Configure GPIO pin Output Level */
  HAL_GPIO_WritePin(GPIOC, SEC_OUT_Pin|ABSOLUTE_ENCODER_CS_Pin, GPIO_PIN_RESET);

  /*Configure GPIO pin Output Level */
  HAL_GPIO_WritePin(GD_WAKE_GPIO_Port, GD_WAKE_Pin, GPIO_PIN_SET);

  /*Configure GPIO pin : SEC_IN_Pin */
  GPIO_InitStruct.Pin = SEC_IN_Pin;
  GPIO_InitStruct.Mode = GPIO_MODE_INPUT;
  GPIO_InitStruct.Pull = GPIO_NOPULL;
  HAL_GPIO_Init(SEC_IN_GPIO_Port, &GPIO_InitStruct);

  /*Configure GPIO pins : SEC_OUT_Pin ABSOLUTE_ENCODER_CS_Pin */
  GPIO_InitStruct.Pin = SEC_OUT_Pin|ABSOLUTE_ENCODER_CS_Pin;
  GPIO_InitStruct.Mode = GPIO_MODE_OUTPUT_PP;
  GPIO_InitStruct.Pull = GPIO_NOPULL;
  GPIO_InitStruct.Speed = GPIO_SPEED_FREQ_LOW;
  HAL_GPIO_Init(GPIOC, &GPIO_InitStruct);

  /*Configure GPIO pin : GD_WAKE_Pin */
  GPIO_InitStruct.Pin = GD_WAKE_Pin;
  GPIO_InitStruct.Mode = GPIO_MODE_OUTPUT_PP;
  GPIO_InitStruct.Pull = GPIO_NOPULL;
  GPIO_InitStruct.Speed = GPIO_SPEED_FREQ_LOW;
  HAL_GPIO_Init(GD_WAKE_GPIO_Port, &GPIO_InitStruct);

  /*Configure GPIO pins : GD_READY_Pin GD_NFAULT_Pin */
  GPIO_InitStruct.Pin = GD_READY_Pin|GD_NFAULT_Pin;
  GPIO_InitStruct.Mode = GPIO_MODE_INPUT;
  GPIO_InitStruct.Pull = GPIO_PULLUP;
  HAL_GPIO_Init(GPIOE, &GPIO_InitStruct);

}

void Error_Handler(void)
{
  __disable_irq();
  while (1)
  {
  }
}

/************************ (C) COPYRIGHT STMicroelectronics *****END OF FILE****/
